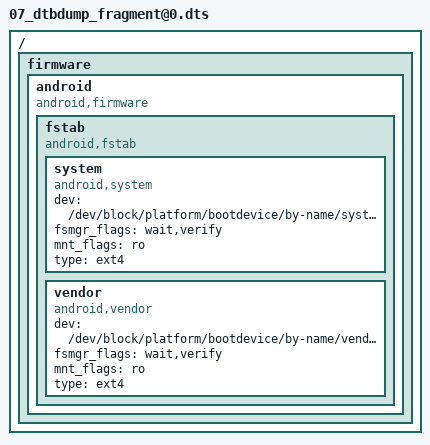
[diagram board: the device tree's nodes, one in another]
/dts-v1/;

/ {

	__fixups__ {
		accdet = "/fragment@17:target:0", "/fragment@65:target:0";
		apuart0 = "/fragment@22:target:0";
		audgpio = "/fragment@18:target:0";
		auxadc = "/fragment@45:target:0";
		charger = "/fragment@34:target:0";
		chosen = "/fragment@0:target:0";
		consys = "/fragment@21:target:0";
		fpc_interrupt = "/fragment@41:target:0";
		goodix_fp = "/fragment@67:target:0";
		goodix_optical_fp = "/fragment@39:target:0";
		gpio = "/fragment@60:target:0";
		gpio_usage_mapping = "/fragment@59:target:0";
		gyro = "/fragment@64:target:0";
		i2c0 = "/fragment@13:target:0", "/fragment@47:target:0";
		i2c1 = "/fragment@48:target:0";
		i2c10 = "/fragment@57:target:0";
		i2c11 = "/fragment@58:target:0";
		i2c2 = "/fragment@49:target:0";
		i2c3 = "/fragment@4:target:0", "/fragment@7:target:0", "/fragment@50:target:0";
		i2c4 = "/fragment@51:target:0";
		i2c5 = "/fragment@9:target:0", "/fragment@52:target:0";
		i2c6 = "/fragment@53:target:0", "/fragment@84:target:0";
		i2c7 = "/fragment@54:target:0";
		i2c8 = "/fragment@55:target:0";
		i2c9 = "/fragment@56:target:0";
		irtx_pwm = "/fragment@26:target:0";
		kd_camera_hw1 = "/fragment@25:target:0", "/fragment@81:target:0";
		keypad = "/fragment@30:target:0", "/fragment@83:target:0";
		main_pmic = "/fragment@70:target:0";
		md1_sim1_hot_plug_eint = "/fragment@72:target:0";
		md1_sim2_hot_plug_eint = "/fragment@73:target:0";
		mediatek_phy_tuning = "/fragment@2:target:0";
		motor_drv = "/fragment@12:target:0";
		motor_pl = "/fragment@11:target:0";
		mrdump_ext_rst = "/fragment@61:target:0";
		msdc1 = "/fragment@32:target:0";
		msdc1_ins = "/fragment@63:target:0";
		mt6370_pmu = "/fragment@28:target:0";
		mt6370_typec = "/fragment@29:target:0";
		mt_pmic_vcama1_ldo_reg = "/fragment@25/__overlay__:cam0_vcama-supply:0", "/fragment@74:target:0", "/fragment@81/__overlay__:vcama-supply:0";
		mt_pmic_vcama2_ldo_reg = "/fragment@25/__overlay__:cam1_vcama-supply:0", "/fragment@25/__overlay__:cam2_vcama-supply:0", "/fragment@75:target:0", "/fragment@81/__overlay__:vcama_sub-supply:0", "/fragment@81/__overlay__:vcama_main2-supply:0";
		mt_pmic_vcamd_ldo_reg = "/fragment@25/__overlay__:cam2_vcamd-supply:0", "/fragment@78:target:0", "/fragment@81/__overlay__:vcamd_main2-supply:0";
		mt_pmic_vcamio_ldo_reg = "/fragment@25/__overlay__:cam0_vcamio-supply:0", "/fragment@25/__overlay__:cam1_vcamio-supply:0", "/fragment@25/__overlay__:cam2_vcamio-supply:0", "/fragment@79:target:0", "/fragment@81/__overlay__:vcamio-supply:0", "/fragment@81/__overlay__:vcamio_sub-supply:0", "/fragment@81/__overlay__:vcamio_main2-supply:0";
		mt_pmic_vldo28_ldo_reg = "/fragment@80:target:0", "/fragment@81/__overlay__:vcamaf-supply:0", "/fragment@82/__overlay__:vtouch-supply:0";
		mt_pmic_vsim1_ldo_reg = "/fragment@76:target:0";
		mt_pmic_vsim2_ldo_reg = "/fragment@77:target:0";
		mtkfb = "/fragment@6:target:0";
		odm = "/fragment@1:target:0";
		oppo_fp_common = "/fragment@44:target:0";
		otg_iddig = "/fragment@15:target:0", "/fragment@68:target:0";
		pio = "/fragment@1/__overlay__/kpd_volume_up:interrupt-parent:0", "/fragment@1/__overlay__/kpd_volume_down:interrupt-parent:0", "/fragment@1/__overlay__/oppo_devinfo:Hw,sub_hwid_1:0", "/fragment@1/__overlay__/oppo_devinfo:Hw,sub_hwid_2:0", "/fragment@1/__overlay__/oppo_charger:qcom,chargerid_switch-gpio:0", "/fragment@5:target:0", "/fragment@8:target:0", "/fragment@9/__overlay__/bq25601d-charger@6b:interrupt-parent:0", "/fragment@9/__overlay__/bq25601d-charger@6b:chg-irq-gpio:0", "/fragment@9/__overlay__/bq25890h-charger@6a:interrupt-parent:0", "/fragment@9/__overlay__/bq25890h-charger@6a:chg-irq-gpio:0", "/fragment@10:target:0", "/fragment@12/__overlay__:boost-gpio:0", "/fragment@12/__overlay__:sleep-gpio:0", "/fragment@12/__overlay__:dir-gpio:0", "/fragment@12/__overlay__:step-gpio:0", "/fragment@13/__overlay__/dhall0-m1120@0f:interrupt-parent:0", "/fragment@13/__overlay__/dhall0-m1120@0f:dhall,irq-gpio:0", "/fragment@13/__overlay__/dhall0-m1120@0f:hall-power-gpio:0", "/fragment@13/__overlay__/dhall1-m1120@0c:interrupt-parent:0", "/fragment@13/__overlay__/dhall1-m1120@0c:dhall,irq-gpio:0", "/fragment@13/__overlay__/dhall1-m1120@0c:hall-power-gpio:0", "/fragment@14:target:0", "/fragment@16:target:0", "/fragment@19:target:0", "/fragment@20:target:0", "/fragment@23:target:0", "/fragment@24:target:0", "/fragment@27:target:0", "/fragment@28/__overlay__:mt6370,intr_gpio:0", "/fragment@29/__overlay__:mt6370pd,intr_gpio:0", "/fragment@30/__overlay__:keypad,volume-up:0", "/fragment@30/__overlay__:keypad,volume-down:0", "/fragment@31:target:0", "/fragment@33:target:0", "/fragment@35:target:0", "/fragment@36:target:0", "/fragment@37/__overlay__/touchscreen@0:reset-gpio:0", "/fragment@37/__overlay__/touchscreen@0:interrupt-parent:0", "/fragment@37/__overlay__/touchscreen@0:irq-gpio:0", "/fragment@37/__overlay__/touchscreen@0:lcd-reset-gpio:0", "/fragment@38:target:0", "/fragment@39/__overlay__:interrupt-parent:0", "/fragment@39/__overlay__:goodix,gpio_irq:0", "/fragment@39/__overlay__:goodix,gpio_reset:0", "/fragment@39/__overlay__:goodix,gpio_ldo:0", "/fragment@39/__overlay__:goodix,gpio_cs:0", "/fragment@40:target:0", "/fragment@41/__overlay__:fpc,irq-gpio:0", "/fragment@41/__overlay__:fpc,reset-gpio:0", "/fragment@41/__overlay__:fpc,vdd-en:0", "/fragment@41/__overlay__:fpc,gpio_cs:0", "/fragment@42/__overlay__/fingerprint@0:ldo_gpio:0", "/fragment@43:target:0", "/fragment@44/__overlay__:oppo,fp-id0:0", "/fragment@48/__overlay__/alsps@51:interrupt-parent:0", "/fragment@59/__overlay__:GPIO_SIM2_SIO:0", "/fragment@59/__overlay__:GPIO_SIM2_SRST:0", "/fragment@59/__overlay__:GPIO_SIM2_SCLK:0", "/fragment@59/__overlay__:GPIO_SIM1_SCLK:0", "/fragment@59/__overlay__:GPIO_SIM1_SRST:0", "/fragment@59/__overlay__:GPIO_SIM1_SIO:0", "/fragment@59/__overlay__:GPIO_SIM1_HOT_PLUG:0", "/fragment@61/__overlay__:interrupt-parent:0", "/fragment@61/__overlay__:deb-gpios:0", "/fragment@62/__overlay__:interrupt-parent:0", "/fragment@63/__overlay__:interrupt-parent:0", "/fragment@63/__overlay__:deb-gpios:0", "/fragment@64/__overlay__:interrupt-parent:0", "/fragment@65/__overlay__:interrupt-parent:0", "/fragment@65/__overlay__:deb-gpios:0", "/fragment@66/__overlay__:interrupt-parent:0", "/fragment@67/__overlay__:interrupt-parent:0", "/fragment@68/__overlay__:interrupt-parent:0", "/fragment@69/__overlay__:interrupt-parent:0", "/fragment@69/__overlay__:deb-gpios:0", "/fragment@70/__overlay__:interrupt-parent:0", "/fragment@71/__overlay__:interrupt-parent:0", "/fragment@85:target:0", "/fragment@86:target:0";
		pmic_clock_buffer_ctrl = "/fragment@46:target:0";
		rt9465_slave_chr = "/fragment@66:target:0";
		scp = "/fragment@3:target:0";
		smart_pa = "/fragment@71:target:0";
		spi0 = "/fragment@42:target:0";
		spi3 = "/fragment@37:target:0";
		swtp = "/fragment@69:target:0", "/fragment@87:target:0";
		touch = "/fragment@62:target:0", "/fragment@82:target:0";
	};

	__local_fixups__ {

		fragment@1 {

			__overlay__ {

				oppo_charger {
					pinctrl-0 = <0x0>;
					pinctrl-1 = <0x0>;
					pinctrl-2 = <0x0>;
				};

				oppo_devinfo {
					pinctrl-0 = <0x0>;
					pinctrl-1 = <0x0 0x4>;
					pinctrl-2 = <0x0 0x4>;
				};
			};
		};

		fragment@12 {

			__overlay__ {
				pinctrl-0 = <0x0>;
				pinctrl-1 = <0x0 0x4 0x8 0xc>;
				pinctrl-2 = <0x0 0x4 0x8 0xc>;
			};
		};

		fragment@13 {

			__overlay__ {

				dhall0-m1120@0f {
					pinctrl-0 = <0x0>;
					pinctrl-1 = <0x0>;
					pinctrl-2 = <0x0>;
				};

				dhall1-m1120@0c {
					pinctrl-0 = <0x0>;
					pinctrl-1 = <0x0>;
					pinctrl-2 = <0x0>;
				};
			};
		};

		fragment@15 {

			__overlay__ {
				pinctrl-0 = <0x0>;
				pinctrl-1 = <0x0>;
				pinctrl-2 = <0x0>;
			};
		};

		fragment@18 {

			__overlay__ {
				pinctrl-0 = <0x0>;
				pinctrl-1 = <0x0>;
				pinctrl-10 = <0x0>;
				pinctrl-11 = <0x0>;
				pinctrl-2 = <0x0>;
				pinctrl-3 = <0x0>;
				pinctrl-4 = <0x0>;
				pinctrl-5 = <0x0>;
				pinctrl-6 = <0x0>;
				pinctrl-7 = <0x0>;
				pinctrl-8 = <0x0>;
				pinctrl-9 = <0x0>;
			};
		};

		fragment@21 {

			__overlay__ {
				pinctrl-0 = <0x0>;
				pinctrl-1 = <0x0>;
				pinctrl-2 = <0x0>;
				pinctrl-3 = <0x0>;
			};
		};

		fragment@22 {

			__overlay__ {
				pinctrl-0 = <0x0>;
				pinctrl-1 = <0x0>;
				pinctrl-2 = <0x0>;
				pinctrl-3 = <0x0>;
				pinctrl-4 = <0x0>;
				pinctrl-5 = <0x0>;
				pinctrl-6 = <0x0>;
			};
		};

		fragment@25 {

			__overlay__ {
				pinctrl-0 = <0x0>;
				pinctrl-1 = <0x0>;
				pinctrl-10 = <0x0>;
				pinctrl-11 = <0x0>;
				pinctrl-12 = <0x0>;
				pinctrl-13 = <0x0>;
				pinctrl-14 = <0x0>;
				pinctrl-15 = <0x0>;
				pinctrl-16 = <0x0>;
				pinctrl-17 = <0x0>;
				pinctrl-18 = <0x0>;
				pinctrl-19 = <0x0>;
				pinctrl-2 = <0x0>;
				pinctrl-20 = <0x0>;
				pinctrl-21 = <0x0>;
				pinctrl-22 = <0x0>;
				pinctrl-23 = <0x0>;
				pinctrl-24 = <0x0>;
				pinctrl-25 = <0x0>;
				pinctrl-3 = <0x0>;
				pinctrl-4 = <0x0>;
				pinctrl-5 = <0x0>;
				pinctrl-6 = <0x0>;
				pinctrl-7 = <0x0>;
				pinctrl-8 = <0x0>;
				pinctrl-9 = <0x0>;
			};
		};

		fragment@26 {

			__overlay__ {
				pinctrl-0 = <0x0>;
				pinctrl-1 = <0x0>;
			};
		};

		fragment@30 {

			__overlay__ {
				pinctrl-0 = <0x0>;
				pinctrl-1 = <0x0>;
			};
		};

		fragment@32 {

			__overlay__ {
				pinctrl-0 = <0x0>;
				pinctrl-1 = <0x0>;
			};
		};

		fragment@39 {

			__overlay__ {
				pinctrl-0 = <0x0>;
				pinctrl-1 = <0x0>;
				pinctrl-2 = <0x0>;
				pinctrl-3 = <0x0>;
				pinctrl-4 = <0x0>;
			};
		};

		fragment@41 {

			__overlay__ {
				pinctrl-0 = <0x0 0x4 0x8>;
				pinctrl-1 = <0x0>;
			};
		};

		fragment@44 {

			__overlay__ {
				pinctrl-0 = <0x0>;
			};
		};

		fragment@6 {

			__overlay__ {
				pinctrl-0 = <0x0>;
				pinctrl-1 = <0x0>;
				pinctrl-10 = <0x0>;
				pinctrl-11 = <0x0>;
				pinctrl-12 = <0x0>;
				pinctrl-13 = <0x0 0x4>;
				pinctrl-14 = <0x0 0x4>;
				pinctrl-2 = <0x0>;
				pinctrl-3 = <0x0>;
				pinctrl-4 = <0x0>;
				pinctrl-5 = <0x0>;
				pinctrl-6 = <0x0>;
				pinctrl-7 = <0x0>;
				pinctrl-8 = <0x0>;
				pinctrl-9 = <0x0>;
			};
		};

		fragment@7 {

			__overlay__ {

				tfa98xx@35 {
					pinctrl-0 = <0x0>;
					pinctrl-1 = <0x0>;
					pinctrl-2 = <0x0>;
				};
			};
		};

		fragment@84 {

			__overlay__ {
				pinctrl-0 = <0x0>;
				pinctrl-1 = <0x0>;
			};
		};
	};

	__symbols__ {
		alsps_mtk = "/fragment@48/__overlay__/alsps@51";
		aud_clk_mosi_off = "/fragment@19/__overlay__/aud_clk_mosi_off";
		aud_clk_mosi_on = "/fragment@19/__overlay__/aud_clk_mosi_on";
		aud_dat_miso_off = "/fragment@19/__overlay__/aud_dat_miso_off";
		aud_dat_miso_on = "/fragment@19/__overlay__/aud_dat_miso_on";
		aud_dat_mosi_off = "/fragment@19/__overlay__/aud_dat_mosi_off";
		aud_dat_mosi_on = "/fragment@19/__overlay__/aud_dat_mosi_on";
		aud_pins_hpamp_high = "/fragment@19/__overlay__/audhpamphigh";
		aud_pins_hpamp_low = "/fragment@19/__overlay__/audhpamplow";
		aud_pins_i2s0_mode0 = "/fragment@19/__overlay__/audi2s0mode0";
		aud_pins_i2s0_mode1 = "/fragment@19/__overlay__/audi2s0mode1";
		aud_pins_i2s1_mode0 = "/fragment@19/__overlay__/audi2s1mode0";
		aud_pins_i2s1_mode1 = "/fragment@19/__overlay__/audi2s1mode1";
		barometer_mtk = "/fragment@48/__overlay__/barometer@77";
		bat_gm30 = "/fragment@1/__overlay__/bat_gm30";
		boost_active = "/fragment@10/__overlay__/boost_active";
		boost_sleep = "/fragment@10/__overlay__/boost_sleep";
		camera_main_af_mtk = "/fragment@51/__overlay__/camera_main_af@72";
		camera_main_eeprom_mtk = "/fragment@51/__overlay__/camera_main_eeprom@50";
		camera_main_mtk = "/fragment@51/__overlay__/camera_main@1a";
		camera_main_two_af_mtk = "/fragment@51/__overlay__/camera_main_two_af@72";
		camera_main_two_eeprom_mtk = "/fragment@49/__overlay__/camera_main_two_eeprom@51";
		camera_main_two_mtk = "/fragment@49/__overlay__/camera_main_two@10";
		camera_pins_cam0_mclk_2ma = "/fragment@24/__overlay__/camera_pins_cam0_mclk_2ma";
		camera_pins_cam0_mclk_4ma = "/fragment@24/__overlay__/camera_pins_cam0_mclk_4ma";
		camera_pins_cam0_mclk_6ma = "/fragment@24/__overlay__/camera_pins_cam0_mclk_6ma";
		camera_pins_cam0_mclk_8ma = "/fragment@24/__overlay__/camera_pins_cam0_mclk_8ma";
		camera_pins_cam0_mclk_off = "/fragment@24/__overlay__/camera_pins_cam0_mclk_off";
		camera_pins_cam0_rst_0 = "/fragment@24/__overlay__/cam0@0";
		camera_pins_cam0_rst_1 = "/fragment@24/__overlay__/cam0@1";
		camera_pins_cam0_vcamd_0 = "/fragment@24/__overlay__/cam0@vcam0";
		camera_pins_cam0_vcamd_1 = "/fragment@24/__overlay__/cam0@vcam1";
		camera_pins_cam1_mclk_2ma = "/fragment@24/__overlay__/camera_pins_cam1_mclk_2ma";
		camera_pins_cam1_mclk_4ma = "/fragment@24/__overlay__/camera_pins_cam1_mclk_4ma";
		camera_pins_cam1_mclk_6ma = "/fragment@24/__overlay__/camera_pins_cam1_mclk_6ma";
		camera_pins_cam1_mclk_8ma = "/fragment@24/__overlay__/camera_pins_cam1_mclk_8ma";
		camera_pins_cam1_mclk_off = "/fragment@24/__overlay__/camera_pins_cam1_mclk_off";
		camera_pins_cam1_rst_0 = "/fragment@24/__overlay__/cam1@0";
		camera_pins_cam1_rst_1 = "/fragment@24/__overlay__/cam1@1";
		camera_pins_cam1_vcamd_0 = "/fragment@24/__overlay__/cam1@vcamd0";
		camera_pins_cam1_vcamd_1 = "/fragment@24/__overlay__/cam1@vcamd1";
		camera_pins_cam2_mclk_2ma = "/fragment@24/__overlay__/camera_pins_cam2_mclk_2ma";
		camera_pins_cam2_mclk_4ma = "/fragment@24/__overlay__/camera_pins_cam2_mclk_4ma";
		camera_pins_cam2_mclk_6ma = "/fragment@24/__overlay__/camera_pins_cam2_mclk_6ma";
		camera_pins_cam2_mclk_8ma = "/fragment@24/__overlay__/camera_pins_cam2_mclk_8ma";
		camera_pins_cam2_mclk_off = "/fragment@24/__overlay__/camera_pins_cam2_mclk_off";
		camera_pins_cam2_rst_0 = "/fragment@24/__overlay__/cam2@0";
		camera_pins_cam2_rst_1 = "/fragment@24/__overlay__/cam2@1";
		camera_pins_default = "/fragment@24/__overlay__/camdefault";
		camera_sub_eeprom_mtk = "/fragment@51/__overlay__/camera_sub_eeprom@54";
		camera_sub_mtk = "/fragment@51/__overlay__/camera_sub@35";
		cap_touch_mtk = "/fragment@47/__overlay__/cap_touch@5d";
		ccu_sensor_i2c_2_hw_mtk = "/fragment@49/__overlay__/ccu_sensor_i2c_2_hw@36";
		ccu_sensor_i2c_4_hw_mtk = "/fragment@51/__overlay__/ccu_sensor_i2c_4_hw@33";
		charger_pins_default = "/fragment@35/__overlay__/eint0default";
		charger_pins_eint_output0 = "/fragment@35/__overlay__/charger_gpio_as_output_low";
		charger_pins_eint_output1 = "/fragment@35/__overlay__/charger_gpio_as_output_high";
		consys_pins_default = "/fragment@20/__overlay__/consys_default";
		dir_active = "/fragment@10/__overlay__/dir_active";
		dir_sleep = "/fragment@10/__overlay__/dir_sleep";
		fpc_irq_default = "/fragment@40/__overlay__/fpc_irq_default";
		fpc_pwr_default = "/fragment@40/__overlay__/fpc_pwr_default";
		fpc_reset_default = "/fragment@40/__overlay__/fpc_reset_default";
		fuelgauge = "/fragment@1/__overlay__/fuelgauge";
		goodix_irq_no_pull = "/fragment@38/__overlay__/goodix_irq_no_pull";
		goodix_irq_out_low = "/fragment@38/__overlay__/goodix_irq_out_low";
		goodix_ldo_default = "/fragment@38/__overlay__/goodix_ldo_default";
		goodix_reset_default = "/fragment@38/__overlay__/goodix_reset_default";
		gpio41_gpio_mode = "/fragment@16/__overlay__/id_output_low";
		gpio41_mode1_iddig = "/fragment@16/__overlay__/id_init";
		gpio_fpc_cs_func = "/fragment@40/__overlay__/gpio_fpc_cs_func";
		gpio_goodix_cs_func = "/fragment@38/__overlay__/gpio_goodix_cs_func";
		gpio_id0_default = "/fragment@43/__overlay__/gpio_id0_default";
		gpslna_pins_init = "/fragment@20/__overlay__/gpslna@0";
		gpslna_pins_oh = "/fragment@20/__overlay__/gpslna@1";
		gpslna_pins_ol = "/fragment@20/__overlay__/gpslna@2";
		hall0_interrupt_input = "/fragment@14/__overlay__/hall0_interrupt_input";
		hall1_interrupt_input = "/fragment@14/__overlay__/hall1_interrupt_input";
		hall_power_down = "/fragment@14/__overlay__/hall_power_down";
		hall_power_up = "/fragment@14/__overlay__/hall_power_up";
		hw_pins_default = "/fragment@86/__overlay__/default@hw_sub_id";
		hw_pins_sub_id1_active = "/fragment@86/__overlay__/active@id1";
		hw_pins_sub_id1_sleep = "/fragment@86/__overlay__/sleep@id1";
		hw_pins_sub_id2_active = "/fragment@86/__overlay__/active@id2";
		hw_pins_sub_id2_sleep = "/fragment@86/__overlay__/sleep@id2";
		i2c6_i2c_state = "/fragment@85/__overlay__/i2c6_sda_i2c_state";
		i2c6_output_low_state = "/fragment@85/__overlay__/i2c6_sda_output_low_state";
		iddig_default = "/fragment@16/__overlay__/id_default";
		irtx_gpio_led_default = "/fragment@27/__overlay__/irtx_gpio_led_def@gpio90";
		irtx_gpio_led_set = "/fragment@27/__overlay__/irtx_gpio_led_set@gpio90";
		kpd_volume_down = "/fragment@1/__overlay__/kpd_volume_down";
		kpd_volume_up = "/fragment@1/__overlay__/kpd_volume_up";
		led0 = "/fragment@1/__overlay__/led@0";
		led1 = "/fragment@1/__overlay__/led@1";
		led2 = "/fragment@1/__overlay__/led@2";
		led3 = "/fragment@1/__overlay__/led@3";
		led4 = "/fragment@1/__overlay__/led@4";
		led5 = "/fragment@1/__overlay__/led@5";
		led6 = "/fragment@1/__overlay__/led@6";
		motor_default = "/fragment@10/__overlay__/motor_default";
		msdc1_off = "/fragment@33/__overlay__/sd0@1";
		msdc1_on = "/fragment@33/__overlay__/sd0@0";
		msensor_mtk = "/fragment@48/__overlay__/msensor@0c";
		mtkfb_pins_default = "/fragment@5/__overlay__/default";
		mtkfb_pins_lcd_1p8_en0 = "/fragment@5/__overlay__/lcd_1p8_en0_gpio";
		mtkfb_pins_lcd_1p8_en1 = "/fragment@5/__overlay__/lcd_1p8_en1_gpio";
		mtkfb_pins_lcd_bias_enn0 = "/fragment@5/__overlay__/lcd_bias_enn0_gpio";
		mtkfb_pins_lcd_bias_enn1 = "/fragment@5/__overlay__/lcd_bias_enn1_gpio";
		mtkfb_pins_lcd_bias_enp0 = "/fragment@5/__overlay__/lcd_bias_enp0_gpio";
		mtkfb_pins_lcd_bias_enp1 = "/fragment@5/__overlay__/lcd_bias_enp1_gpio";
		mtkfb_pins_lcd_bl_en0 = "/fragment@5/__overlay__/lcd_bl_en0_gpio";
		mtkfb_pins_lcd_bl_en1 = "/fragment@5/__overlay__/lcd_bl_en1_gpio";
		mtkfb_pins_lcm_reset0 = "/fragment@5/__overlay__/lcm_rst_out0_gpio";
		mtkfb_pins_lcm_reset1 = "/fragment@5/__overlay__/lcm_rst_out1_gpio";
		mtkfb_pins_mode_te_gpio = "/fragment@5/__overlay__/mode_te_gpio";
		mtkfb_pins_mode_te_te = "/fragment@5/__overlay__/mode_te_te";
		mtkfb_pins_spi_clk_en0 = "/fragment@5/__overlay__/spi_clk_en0_gpio";
		mtkfb_pins_spi_clk_en1 = "/fragment@5/__overlay__/spi_clk_en1_gpio";
		mtkfb_pins_spi_cs_en0 = "/fragment@5/__overlay__/spi_csn_en0_gpio";
		mtkfb_pins_spi_cs_en1 = "/fragment@5/__overlay__/spi_csn_en1_gpio";
		nfc_mtk = "/fragment@50/__overlay__/nfc@08";
		oppo_charger = "/fragment@1/__overlay__/oppo_charger";
		oppo_devinfo = "/fragment@1/__overlay__/oppo_devinfo";
		oppo_fp = "/fragment@42/__overlay__/fingerprint@0";
		oppo_project = "/fragment@1/__overlay__/oppo_project";
		oppo_sensor = "/fragment@1/__overlay__/oppo_sensor";
		pwm_active = "/fragment@10/__overlay__/pwm_active";
		pwm_sleep = "/fragment@10/__overlay__/pwm_sleep";
		slave_charger_mtk = "/fragment@53/__overlay__/slave_charger@4b";
		sleep_active = "/fragment@10/__overlay__/sleep_active";
		sleep_sleep = "/fragment@10/__overlay__/sleep_sleep";
		speaker_amp_mtk = "/fragment@53/__overlay__/speaker_amp@34";
		strobe_main_2_mtk = "/fragment@51/__overlay__/strobe_main_2@64";
		strobe_main_mtk = "/fragment@51/__overlay__/strobe_main@63";
		subpmic_pmu_mtk = "/fragment@52/__overlay__/subpmic_pmu@37";
		tfa98xxresetdefault = "/fragment@8/__overlay__/tfa98xxrstdefault";
		tfa98xxresethigh = "/fragment@8/__overlay__/tfa98xxrsthigh";
		tfa98xxresetlow = "/fragment@8/__overlay__/tfa98xxrstlow";
		uart0_gpio_def_cfg = "/fragment@23/__overlay__/uart0gpiodefault";
		uart0_rx_clr_cfg = "/fragment@23/__overlay__/uart0_rx_clear@gpio95";
		uart0_rx_gpio_input = "/fragment@23/__overlay__/uart0_rx_gpio@gpio95";
		uart0_rx_set_cfg = "/fragment@23/__overlay__/uart0_rx_set@gpio95";
		uart0_tx_clr_cfg = "/fragment@23/__overlay__/uart0_tx_clear@gpio96";
		uart0_tx_gpio_input = "/fragment@23/__overlay__/uart0_tx_gpio@gpio96";
		uart0_tx_set_cfg = "/fragment@23/__overlay__/uart0_tx_set@gpio96";
		usb_c_pinctrl = "/fragment@1/__overlay__/usb_c_pinctrl";
		usb_type_c_mtk = "/fragment@52/__overlay__/usb_type_c@4e";
		vibrator0 = "/fragment@1/__overlay__/vibrator@0";
		volume_down_gpio_eint = "/fragment@31/__overlay__/volume_down@0";
		volume_up_gpio_eint = "/fragment@31/__overlay__/volume_up@0";
	};

	firmware {

		android {
			compatible = "android,firmware";

			fstab {
				compatible = "android,fstab";

				system {
					compatible = "android,system";
					dev = "/dev/block/platform/bootdevice/by-name/system";
					fsmgr_flags = "wait,verify";
					mnt_flags = "ro";
					type = "ext4";
				};

				vendor {
					compatible = "android,vendor";
					dev = "/dev/block/platform/bootdevice/by-name/vendor";
					fsmgr_flags = "wait,verify";
					mnt_flags = "ro";
					type = "ext4";
				};
			};
		};
	};

	fragment@0 {
		target = <0xffffffff>;

		__overlay__ {
			atag,videolfb-fb_base_h = <0x0>;
			atag,videolfb-fb_base_l = "^`P";
			atag,videolfb-fps = <0x1770>;
			atag,videolfb-islcm_inited = <0x0>;
			atag,videolfb-islcmfound = <0x1>;
			atag,videolfb-lcmname = "nt35595_fhd_dsi_cmd_truly_nt50358_drv";
			atag,videolfb-vramSize = <0x17bb000>;
		};
	};

	fragment@1 {
		target = <0xffffffff>;

		__overlay__ {

			bat_gm30 {
				CAR_TUNE_VALUE = <0x64>;
				DIFFERENCE_FULLOCV_ITH = <0x15e>;
				EMBEDDED_SEL = <0x1>;
				FG_METER_RESISTANCE = <0x32>;
				KEEP_100_PERCENT = <0x3>;
				PMIC_MIN_VOL = <0x85fc>;
				PMIC_SHUTDOWN_CURRENT = <0x14>;
				POWERON_SYSTEM_IBOOT = <0x1f4>;
				Q_MAX_SYS_VOLTAGE_BAT0 = <0xd16>;
				Q_MAX_SYS_VOLTAGE_BAT1 = <0xd16>;
				Q_MAX_SYS_VOLTAGE_BAT2 = <0xd16>;
				Q_MAX_SYS_VOLTAGE_BAT3 = <0xd16>;
				R_FG_VALUE = <0xa>;
				SHUTDOWN_1_TIME = <0x3c>;
				SHUTDOWN_GAUGE0_VOLTAGE = <0x84d0>;
				TEMPERATURE_T0 = <0x32>;
				TEMPERATURE_T1 = <0x19>;
				TEMPERATURE_T2 = <0xa>;
				TEMPERATURE_T3 = <0x0>;
				TEMPERATURE_T4 = <0xfffffff6>;
				battery0_profile_t0 = <0x0 0xaad2 0x401 0x194 0xaa51 0x401 0x328 0xa9dc 0x410 0x4bc 0xa965 0x40f 0x651 0xa8ef 0x407 0x7e5 0xa885 0x41a 0x979 0xa80c 0x41a 0xb0d 0xa792 0x409 0xca1 0xa719 0x401 0xe35 0xa6a3 0x408 0xfc9 0xa632 0x41d 0x115e 0xa5c0 0x431 0x12f2 0xa548 0x421 0x1486 0xa4d4 0x427 0x161a 0xa463 0x43b 0x17ae 0xa3f0 0x445 0x1942 0xa377 0x41c 0x1ad6 0xa303 0x41a 0x1c6b 0xa28c 0x41a 0x1dff 0xa21a 0x424 0x1f93 0xa1af 0x433 0x2127 0xa13e 0x433 0x22bb 0xa0d5 0x448 0x244f 0xa066 0x43c 0x25e3 0x9ffd 0x43e 0x2778 0x9f9a 0x44c 0x290c 0x9f31 0x44c 0x2aa0 0x9ec8 0x44c 0x2c34 0x9e65 0x44c 0x2dc8 0x9e04 0x44c 0x2f5c 0x9da6 0x45b 0x30f0 0x9d49 0x47e 0x3285 0x9ce0 0x47e 0x3419 0x9c7e 0x46c 0x35ad 0x9c2d 0x473 0x3741 0x9bde 0x487 0x38d5 0x9b85 0x497 0x3a69 0x9b2c 0x497 0x3bfd 0x9ae2 0x4be 0x3d92 0x9a8d 0x4d8 0x3f26 0x9a2f 0x4ec 0x40ba 0x99c0 0x4e0 0x424e 0x992f 0x47b 0x43e2 0x989d 0x42a 0x4576 0x9833 0x41a 0x470a 0x97df 0x425 0x489f 0x9797 0x42c 0x4a33 0x974f 0x41c 0x4bc7 0x9717 0x430 0x4d5b 0x96de 0x433 0x4eef 0x96a0 0x427 0x5083 0x9663 0x41a 0x5217 0x962b 0x41a 0x53ab 0x95fb 0x41a 0x5540 0x95d2 0x42c 0x56d4 0x959f 0x426 0x5868 0x956d 0x42b 0x59fc 0x9544 0x448 0x5b90 0x951b 0x433 0x5d24 0x94f3 0x433 0x5eb8 0x94ca 0x442 0x604d 0x94a6 0x44c 0x61e1 0x9483 0x447 0x6375 0x945b 0x434 0x6509 0x943b 0x448 0x669d 0x9420 0x45c 0x6831 0x9403 0x465 0x69c5 0x93e0 0x465 0x6b5a 0x93b6 0x463 0x6cee 0x937e 0x44f 0x6e82 0x9330 0x429 0x7016 0x92e9 0x427 0x71aa 0x92af 0x433 0x733e 0x927f 0x437 0x74d2 0x9256 0x44b 0x7667 0x9226 0x439 0x77fb 0x91f6 0x433 0x798f 0x91c9 0x433 0x7b23 0x91a3 0x433 0x7cb7 0x9182 0x433 0x7e4b 0x9162 0x45b 0x7fdf 0x9129 0x456 0x8174 0x90e8 0x442 0x8308 0x90a8 0x433 0x849c 0x9067 0x433 0x8630 0x901e 0x433 0x87c4 0x8fd5 0x412 0x8958 0x8fb1 0x40d 0x8aec 0x8fa9 0x427 0x8c81 0x8fa0 0x44c 0x8e15 0x8f90 0x44c 0x8fa9 0x8f79 0x481 0x913d 0x8f41 0x4a4 0x92d1 0x8e98 0x48f 0x9465 0x8d48 0x456 0x95f9 0x8b6b 0x493 0x978e 0x88e1 0x4d0 0x9922 0x853c 0x545 0x9ab6 0x7e14 0xd68 0x9c4a 0x7026 0x1211>;
				battery0_profile_t0_num = <0x64>;
				battery0_profile_t1 = <0x0 0xaa96 0x4c9 0x194 0xaa15 0x4c9 0x328 0xa9a6 0x4e8 0x4bc 0xa934 0x4f0 0x651 0xa8ba 0x4e2 0x7e5 0xa83f 0x4e2 0x979 0xa7c6 0x4e2 0xb0d 0xa75a 0x4f3 0xca1 0xa6e7 0x4ef 0xe35 0xa671 0x4e9 0xfc9 0xa600 0x4fb 0x115e 0xa58e 0x4fb 0x12f2 0xa516 0x4fb 0x1486 0xa4a2 0x4fb 0x161a 0xa42e 0x4f3 0x17ae 0xa3b6 0x4e6 0x1942 0xa345 0x4fa 0x1ad6 0xa2d3 0x4fb 0x1c6b 0xa261 0x4fb 0x1dff 0xa1f2 0x505 0x1f93 0xa187 0x514 0x2127 0xa116 0x514 0x22bb 0xa0ad 0x514 0x244f 0xa03e 0x514 0x25e3 0x9fd5 0x514 0x2778 0x9f74 0x521 0x290c 0x9f12 0x546 0x2aa0 0x9eb9 0x546 0x2c34 0x9e52 0x557 0x2dc8 0x9dee 0x56c 0x2f5c 0x9d87 0x578 0x30f0 0x9d17 0x578 0x3285 0x9cae 0x578 0x3419 0x9c4a 0x58b 0x35ad 0x9bee 0x59f 0x3741 0x9b99 0x5b3 0x38d5 0x9b4a 0x5cc 0x3a69 0x9b01 0x5f4 0x3bfd 0x9ab8 0x609 0x3d92 0x9a58 0x60e 0x3f26 0x99e2 0x5e5 0x40ba 0x995c 0x58e 0x424e 0x98c9 0x529 0x43e2 0x9858 0x4ed 0x4576 0x97fb 0x4e2 0x470a 0x97ab 0x4d6 0x489f 0x9766 0x4c9 0x4a33 0x9726 0x4c9 0x4bc7 0x96ed 0x4c9 0x4d5b 0x96b5 0x4c9 0x4eef 0x967c 0x4c9 0x5083 0x9643 0x4c9 0x5217 0x960c 0x4cd 0x53ab 0x95e4 0x4e1 0x5540 0x95b4 0x4e2 0x56d4 0x9589 0x4e2 0x5868 0x9561 0x4ec 0x59fc 0x9538 0x4fb 0x5b90 0x9510 0x4fb 0x5d24 0x94e7 0x4fb 0x5eb8 0x94c5 0x4fb 0x604d 0x94a4 0x506 0x61e1 0x9484 0x514 0x6375 0x9464 0x516 0x6509 0x944c 0x52a 0x669d 0x9426 0x51c 0x6831 0x9407 0x520 0x69c5 0x93e9 0x526 0x6b5a 0x93c2 0x517 0x6cee 0x93a1 0x52b 0x6e82 0x9379 0x51b 0x7016 0x9346 0x4f9 0x71aa 0x9314 0x4d9 0x733e 0x92ec 0x4cd 0x74d2 0x92c3 0x4e1 0x7667 0x929b 0x4e2 0x77fb 0x926d 0x4d3 0x798f 0x9248 0x4d3 0x7b23 0x922c 0x4e2 0x7cb7 0x9203 0x4e2 0x7e4b 0x91ca 0x4cd 0x7fdf 0x918a 0x4d9 0x8174 0x9152 0x4ed 0x8308 0x911a 0x4f4 0x849c 0x90d0 0x4e2 0x8630 0x9080 0x4e2 0x87c4 0x904a 0x4d1 0x8958 0x9033 0x4e2 0x8aec 0x9028 0x4fb 0x8c81 0x9018 0x4fb 0x8e15 0x9007 0x4fb 0x8fa9 0x8ff7 0x546 0x913d 0x8fa3 0x55f 0x92d1 0x8ec3 0x55f 0x9465 0x8d36 0x563 0x95f9 0x8b19 0x578 0x978e 0x8815 0x5ef 0x9922 0x8366 0x70e 0x9ab6 0x7a4a 0x1a58 0x9c4a 0x74a4 0x1ccf>;
				battery0_profile_t1_num = <0x64>;
				battery0_profile_t2 = <0x0 0xa9f6 0x78a 0x194 0xa96d 0x786 0x328 0xa8f0 0x7b3 0x4bc 0xa872 0x7db 0x651 0xa7f3 0x7e9 0x7e5 0xa77a 0x7e9 0x979 0xa6fe 0x7e9 0xb0d 0xa68b 0x7e9 0xca1 0xa615 0x7f5 0xe35 0xa59c 0x7fb 0xfc9 0xa525 0x7ee 0x115e 0xa4bc 0x817 0x12f2 0xa444 0x809 0x1486 0xa3cf 0x802 0x161a 0xa35c 0x802 0x17ae 0xa2eb 0x802 0x1942 0xa27a 0x802 0x1ad6 0xa209 0x802 0x1c6b 0xa19d 0x81f 0x1dff 0xa134 0x834 0x1f93 0xa0c9 0x834 0x2127 0xa058 0x834 0x22bb 0x9ff7 0x849 0x244f 0x9f95 0x84d 0x25e3 0x9f38 0x864 0x2778 0x9edf 0x893 0x290c 0x9e83 0x8cc 0x2aa0 0x9e12 0x8e0 0x2c34 0x9d8c 0x8c0 0x2dc8 0x9d03 0x8a4 0x2f5c 0x9c86 0x8a0 0x30f0 0x9c21 0x8b7 0x3285 0x9bd9 0x8df 0x3419 0x9b90 0x8e3 0x35ad 0x9b41 0x8f1 0x3741 0x9aef 0x8fc 0x38d5 0x9a9e 0x900 0x3a69 0x9a4d 0x915 0x3bfd 0x99dd 0x8d9 0x3d92 0x9959 0x87f 0x3f26 0x98d4 0x824 0x40ba 0x985c 0x7e4 0x424e 0x97fb 0x7cf 0x43e2 0x97aa 0x7bb 0x4576 0x975f 0x7b7 0x470a 0x971a 0x7ab 0x489f 0x96df 0x7ac 0x4a33 0x96ad 0x7ce 0x4bc7 0x966c 0x7ba 0x4d5b 0x963a 0x7c9 0x4eef 0x9609 0x7d0 0x5083 0x95d9 0x7d0 0x5217 0x95a9 0x7d3 0x53ab 0x9581 0x7e7 0x5540 0x9550 0x7e9 0x56d4 0x9525 0x7f7 0x5868 0x94fd 0x802 0x59fc 0x94d6 0x807 0x5b90 0x94b6 0x81b 0x5d24 0x9496 0x82f 0x5eb8 0x946f 0x825 0x604d 0x944f 0x826 0x61e1 0x9437 0x83a 0x6375 0x941e 0x84d 0x6509 0x9406 0x84d 0x669d 0x93e7 0x84d 0x6831 0x93cb 0x84d 0x69c5 0x93b6 0x854 0x6b5a 0x93a4 0x866 0x6cee 0x9383 0x866 0x6e82 0x936a 0x878 0x7016 0x9347 0x871 0x71aa 0x931e 0x866 0x733e 0x92f4 0x866 0x74d2 0x92c4 0x866 0x7667 0x92a3 0x87a 0x77fb 0x927d 0x88e 0x798f 0x9250 0x8a2 0x7b23 0x921e 0x8bb 0x7cb7 0x91e5 0x8e3 0x7e4b 0x91a3 0x8f8 0x7fdf 0x916f 0x93d 0x8174 0x9127 0x960 0x8308 0x90d4 0x96d 0x849c 0x908f 0x996 0x8630 0x906f 0x9be 0x87c4 0x905c 0x9f8 0x8958 0x904c 0xa4e 0x8aec 0x9039 0xab3 0x8c81 0x901d 0xb1e 0x8e15 0x8feb 0xbae 0x8fa9 0x8f15 0xc03 0x913d 0x8d8a 0xc9a 0x92d1 0x8b60 0xd9a 0x9465 0x887a 0xf1f 0x95f9 0x845f 0x1140 0x978e 0x7a1c 0x22ed 0x9922 0x7044 0x133d 0x9ab6 0x7044 0x133d 0x9c4a 0x7044 0x133d>;
				battery0_profile_t2_num = <0x64>;
				battery0_profile_t3 = <0x0 0xa8fc 0xd16 0x194 0xa84a 0xd16 0x328 0xa7b1 0xd63 0x4bc 0xa728 0xda8 0x651 0xa6a8 0xdd1 0x7e5 0xa62d 0xdfa 0x979 0xa5bc 0xe22 0xb0d 0xa53e 0xe18 0xca1 0xa4c1 0xe10 0xe35 0xa44b 0xe1f 0xfc9 0xa3d9 0xe42 0x115e 0xa366 0xe42 0x12f2 0xa2fc 0xe54 0x1486 0xa28d 0xe69 0x161a 0xa21c 0xe74 0x17ae 0xa1ab 0xe74 0x1942 0xa13a 0xe74 0x1ad6 0xa0d0 0xe88 0x1c6b 0xa066 0xe8d 0x1dff 0xa000 0xea2 0x1f93 0x9fa3 0xed0 0x2127 0x9f52 0xf0d 0x22bb 0x9ef9 0xf49 0x244f 0x9e93 0xf55 0x25e3 0x9e13 0xf4a 0x2778 0x9d7f 0xf2f 0x290c 0x9ce7 0xf06 0x2aa0 0x9c5b 0xedd 0x2c34 0x9bf5 0xefc 0x2dc8 0x9b9e 0xf24 0x2f5c 0x9b54 0xf55 0x30f0 0x9b12 0xf87 0x3285 0x9ac9 0xf87 0x3419 0x9a79 0xf87 0x35ad 0x9a15 0xf79 0x3741 0x99a7 0xf51 0x38d5 0x9934 0xf0f 0x3a69 0x98bb 0xebf 0x3bfd 0x984a 0xe96 0x3d92 0x97eb 0xe6e 0x3f26 0x9797 0xe66 0x40ba 0x9748 0xe74 0x424e 0x9700 0xe73 0x43e2 0x96c0 0xe5f 0x4576 0x9685 0xe7d 0x470a 0x964c 0xe8d 0x489f 0x9616 0xe9c 0x4a33 0x95e5 0xec2 0x4bc7 0x95b5 0xed6 0x4d5b 0x9584 0xeea 0x4eef 0x9559 0xf0c 0x5083 0x952d 0xf2c 0x5217 0x9500 0xf44 0x53ab 0x94df 0xf6d 0x5540 0x94b7 0xf82 0x56d4 0x9494 0xfa5 0x5868 0x9470 0xfc3 0x59fc 0x944c 0xfdd 0x5b90 0x9433 0x1005 0x5d24 0x941b 0x102d 0x5eb8 0x9409 0x1066 0x604d 0x93f5 0x1097 0x61e1 0x93df 0x10c0 0x6375 0x93cf 0x10e8 0x6509 0x93bf 0x1111 0x669d 0x93ae 0x115b 0x6831 0x939e 0x11b8 0x69c5 0x938b 0x120e 0x6b5a 0x9372 0x1248 0x6cee 0x9352 0x1271 0x6e82 0x932a 0x1287 0x7016 0x9307 0x12c3 0x71aa 0x92e0 0x1314 0x733e 0x92af 0x1361 0x74d2 0x927e 0x139f 0x7667 0x924d 0x1416 0x77fb 0x920b 0x1481 0x798f 0x91c6 0x14e6 0x7b23 0x9186 0x1555 0x7cb7 0x9144 0x15e3 0x7e4b 0x90ec 0x1670 0x7fdf 0x90a6 0x171d 0x8174 0x9072 0x17ca 0x8308 0x9051 0x188f 0x849c 0x9040 0x1998 0x8630 0x9027 0x1ab2 0x87c4 0x9008 0x1c13 0x8958 0x8fcf 0x1da4 0x8aec 0x8f3f 0x1f54 0x8c81 0x8e18 0x2125 0x8e15 0x8c1b 0x236f 0x8fa9 0x8950 0x2703 0x913d 0x853c 0x2ca1 0x92d1 0x7eb5 0x3132 0x9465 0x72a6 0x17ed 0x95f9 0x72a6 0x17ed 0x978e 0x72a6 0x17ed 0x9922 0x72a6 0x17ed 0x9ab6 0x72a6 0x17ed 0x9c4a 0x72a6 0x17ed>;
				battery0_profile_t3_num = <0x64>;
				battery0_profile_t4 = <0x0 0xa8ac 0xf55 0x194 0xa7ea 0xf55 0x328 0xa74d 0xfc1 0x4bc 0xa6cb 0xeb4 0x651 0xa651 0xd5c 0x7e5 0xa5c9 0xe82 0x979 0xa550 0xf38 0xb0d 0xa4dd 0xfcc 0xca1 0xa467 0x1035 0xe35 0xa3ee 0x107e 0xfc9 0xa376 0x10b3 0x115e 0xa304 0x10b3 0x12f2 0xa293 0x10e9 0x1486 0xa21d 0x10fe 0x161a 0xa1aa 0x1117 0x17ae 0xa141 0x1145 0x1942 0xa0d8 0x1131 0x1ad6 0xa067 0x10f7 0x1c6b 0xa002 0x10f3 0x1dff 0x9fa4 0x111a 0x1f93 0x9f4d 0x1161 0x2127 0x9efa 0x11c6 0x22bb 0x9e89 0x11b1 0x244f 0x9e05 0x118d 0x25e3 0x9d58 0x1139 0x2778 0x9ca0 0x1104 0x290c 0x9c10 0x1162 0x2aa0 0x9b96 0x1162 0x2c34 0x9b3f 0x1184 0x2dc8 0x9aee 0x11ac 0x2f5c 0x9a8f 0x11b8 0x30f0 0x9a2a 0x11c4 0x3285 0x9a5a 0x1359 0x3419 0x9a10 0x109e 0x35ad 0x99a1 0x1045 0x3741 0x9924 0x1145 0x38d5 0x98a6 0x1214 0x3a69 0x9835 0x12a1 0x3bfd 0x97db 0x126d 0x3d92 0x9788 0x1296 0x3f26 0x973b 0x1285 0x40ba 0x96f4 0x1234 0x424e 0x96b3 0x125d 0x43e2 0x9671 0x12d9 0x4576 0x9637 0x1332 0x470a 0x9603 0x136d 0x489f 0x95d0 0x1395 0x4a33 0x9599 0x13b1 0x4bc7 0x9570 0x134c 0x4d5b 0x9541 0x134e 0x4eef 0x9515 0x1356 0x5083 0x94f0 0x135e 0x5217 0x94ce 0x136c 0x53ab 0x94a6 0x1358 0x5540 0x947d 0x1369 0x56d4 0x945a 0x137d 0x5868 0x943d 0x139a 0x59fc 0x9425 0x13c3 0x5b90 0x940d 0x13eb 0x5d24 0x93fc 0x143b 0x5eb8 0x93ec 0x147e 0x604d 0x93db 0x14b0 0x61e1 0x93cb 0x14df 0x6375 0x93bb 0x151c 0x6509 0x93ab 0x156d 0x669d 0x939b 0x15ce 0x6831 0x9386 0x161c 0x69c5 0x936e 0x1659 0x6b5a 0x9355 0x1697 0x6cee 0x9334 0x16e8 0x6e82 0x9306 0x1727 0x7016 0x92db 0x177e 0x71aa 0x92b2 0x180a 0x733e 0x9289 0x18e7 0x74d2 0x9258 0x1a2a 0x7667 0x9211 0x1aec 0x77fb 0x91ce 0x1be6 0x798f 0x9190 0x1cd6 0x7b23 0x9151 0x1da6 0x7cb7 0x9101 0x1ec1 0x7e4b 0x90a8 0x1f78 0x7fdf 0x9073 0x206b 0x8174 0x9053 0x21da 0x8308 0x903b 0x2372 0x849c 0x9023 0x2487 0x8630 0x900a 0x26c8 0x87c4 0x8fde 0x28ef 0x8958 0x8f5b 0x2b10 0x8aec 0x8e45 0x2d9e 0x8c81 0x8c6e 0x310a 0x8e15 0x89d8 0x3539 0x8fa9 0x8607 0x3af0 0x913d 0x8021 0x38c3 0x92d1 0x740e 0x1aa9 0x9465 0x740e 0x1aa9 0x95f9 0x740e 0x1aa9 0x978e 0x740e 0x1aa9 0x9922 0x740e 0x1aa9 0x9ab6 0x740e 0x1aa9 0x9c4a 0x740e 0x1aa9>;
				battery0_profile_t4_num = <0x64>;
				battery1_profile_t0 = <0x0 0xaab4 0x401 0x199 0xaa18 0x401 0x333 0xa983 0x3f1 0x4cc 0xa8fc 0x3e8 0x665 0xa883 0x3f7 0x7fe 0xa80e 0x414 0x998 0xa78b 0x3eb 0xb31 0xa70f 0x3e8 0xcca 0xa69a 0x3f6 0xe64 0xa623 0x401 0xffd 0xa5a8 0x401 0x1196 0xa536 0x402 0x1330 0xa4c3 0x417 0x14c9 0xa451 0x409 0x1662 0xa3d9 0x401 0x17fb 0xa361 0x3f9 0x1995 0xa2f0 0x3ec 0x1b2e 0xa283 0x400 0x1cc7 0xa211 0x401 0x1e61 0xa1a4 0x410 0x1ffa 0xa129 0x40f 0x2193 0xa0a7 0x40e 0x232c 0xa03d 0x431 0x24c6 0x9fd0 0x41c 0x265f 0x9f6d 0x41a 0x27f8 0x9f16 0x41a 0x2992 0x9ebc 0x423 0x2b2b 0x9e5a 0x42e 0x2cc4 0x9df8 0x41a 0x2e5d 0x9d94 0x41a 0x2ff7 0x9d38 0x42a 0x3190 0x9cd9 0x433 0x3329 0x9c7d 0x43a 0x34c3 0x9c2a 0x449 0x365c 0x9bcf 0x435 0x37f5 0x9b75 0x459 0x398f 0x9b1a 0x465 0x3b28 0x9ac3 0x46f 0x3cc1 0x9a76 0x484 0x3e5a 0x9a33 0x498 0x3ff4 0x99d9 0x4ad 0x418d 0x996b 0x49f 0x4326 0x98ee 0x465 0x44c0 0x9870 0x423 0x4659 0x9801 0x401 0x47f2 0x97a7 0x401 0x498b 0x9764 0x415 0x4b25 0x9723 0x41a 0x4cbe 0x96e1 0x40f 0x4e57 0x96a2 0x401 0x4ff1 0x966a 0x401 0x518a 0x9638 0x401 0x5323 0x95ff 0x401 0x54bd 0x95cb 0x401 0x5656 0x959e 0x401 0x57ef 0x9573 0x401 0x5988 0x9542 0x401 0x5b22 0x9519 0x401 0x5cbb 0x94ef 0x401 0x5e54 0x94cb 0x401 0x5fee 0x94aa 0x410 0x6187 0x9488 0x430 0x6320 0x945f 0x41c 0x64b9 0x9445 0x42d 0x6653 0x93e1 0x424 0x67ec 0x93bf 0x42e 0x6985 0x93e7 0x44c 0x6b1f 0x93ce 0x44c 0x6cb8 0x93a5 0x44c 0x6e51 0x9375 0x43b 0x6feb 0x932f 0x419 0x7184 0x92e3 0x409 0x731d 0x92a6 0x41e 0x74b6 0x927d 0x432 0x7650 0x9244 0x40b 0x77e9 0x9217 0x410 0x7982 0x91ea 0x40f 0x7b1c 0x91b2 0x401 0x7cb5 0x9177 0x403 0x7e4e 0x916f 0x418 0x7fe7 0x9151 0x42c 0x8181 0x9120 0x425 0x831a 0x90e3 0x408 0x84b3 0x90a5 0x3f1 0x864d 0x9073 0x41b 0x87e6 0x9039 0x42f 0x897f 0x8fec 0x412 0x8b18 0x8fb2 0x3f5 0x8cb2 0x8f98 0x3fe 0x8e4b 0x8f96 0x436 0x8fe4 0x8f85 0x44a 0x917e 0x8f75 0x472 0x9317 0x8f4d 0x49b 0x94b0 0x8ec2 0x491 0x964a 0x8da4 0x470 0x97e3 0x8be8 0x498 0x997c 0x898a 0x4ad 0x9b15 0x8637 0x505 0x9caf 0x8051 0x720 0x9e48 0x7594 0x1f72>;
				battery1_profile_t0_num = <0x64>;
				battery1_profile_t1 = <0x0 0xaa50 0x52d 0x199 0xa9b4 0x52d 0x333 0xa932 0x54d 0x4cc 0xa8b6 0x55f 0x665 0xa83a 0x55f 0x7fe 0xa7c0 0x55f 0x998 0xa74e 0x55f 0xb31 0xa6d3 0x55f 0xcca 0xa65e 0x55f 0xe64 0xa5ec 0x55f 0xffd 0xa576 0x55a 0x1196 0xa4fa 0x546 0x1330 0xa487 0x546 0x14c9 0xa415 0x546 0x1662 0xa3a2 0x546 0x17fb 0xa32f 0x53e 0x1995 0xa2bc 0x531 0x1b2e 0xa247 0x545 0x1cc7 0xa1dd 0x546 0x1e61 0xa172 0x555 0x1ffa 0xa108 0x55f 0x2193 0xa09d 0x55f 0x232c 0xa032 0x55d 0x24c6 0x9fbd 0x548 0x265f 0x9f59 0x546 0x27f8 0x9ef7 0x546 0x2992 0x9e98 0x558 0x2b2b 0x9e3c 0x578 0x2cc4 0x9dda 0x578 0x2e5d 0x9d6d 0x58d 0x2ff7 0x9d09 0x591 0x3190 0x9ca7 0x591 0x3329 0x9c4b 0x598 0x34c3 0x9bf9 0x5aa 0x365c 0x9ba7 0x5aa 0x37f5 0x9b55 0x5bd 0x398f 0x9b08 0x5e0 0x3b28 0x9ab9 0x5f5 0x3cc1 0x9a63 0x5f5 0x3e5a 0x9a01 0x5f4 0x3ff4 0x999e 0x5df 0x418d 0x9928 0x598 0x4326 0x98ab 0x552 0x44c0 0x9839 0x51c 0x4659 0x97d9 0x4f3 0x47f2 0x977f 0x4ca 0x498b 0x973c 0x4dd 0x4b25 0x96fb 0x4e2 0x4cbe 0x96bd 0x4e2 0x4e57 0x9686 0x4e2 0x4ff1 0x9654 0x4e2 0x518a 0x961a 0x4e2 0x5323 0x95e8 0x4d0 0x54bd 0x95bd 0x4d7 0x5656 0x9593 0x4eb 0x57ef 0x9568 0x4fb 0x5988 0x9537 0x4fb 0x5b22 0x9516 0x4fb 0x5cbb 0x94ef 0x4fb 0x5e54 0x94c6 0x4fb 0x5fee 0x94a3 0x50a 0x6187 0x9489 0x52a 0x6320 0x9468 0x515 0x64b9 0x9447 0x527 0x6653 0x9426 0x52d 0x67ec 0x940a 0x52d 0x6985 0x93ef 0x52d 0x6b1f 0x93ce 0x52f 0x6cb8 0x93b5 0x543 0x6e51 0x9396 0x546 0x6feb 0x936b 0x51f 0x7184 0x933d 0x4fb 0x731d 0x9314 0x4f7 0x74b6 0x92ea 0x4e2 0x7650 0x92b9 0x4ce 0x77e9 0x9295 0x4d9 0x7982 0x9274 0x4ed 0x7b1c 0x9250 0x4f4 0x7cb5 0x9228 0x4e4 0x7e4e 0x9207 0x4f9 0x7fe7 0x91df 0x4fb 0x8181 0x91aa 0x4fb 0x831a 0x9171 0x4fb 0x84b3 0x913a 0x505 0x864d 0x9108 0x52d 0x87e6 0x90c7 0x52d 0x897f 0x9077 0x52d 0x8b18 0x903d 0x52d 0x8cb2 0x901e 0x535 0x8e4b 0x900f 0x550 0x8fe4 0x9006 0x58d 0x917e 0x8fef 0x5b8 0x9317 0x8fc5 0x5ef 0x94b0 0x8f46 0x618 0x964a 0x8e35 0x632 0x97e3 0x8c69 0x65e 0x997c 0x89ee 0x6b1 0x9b15 0x8665 0x76d 0x9caf 0x7fa6 0xee5 0x9e48 0x77ec 0x249f>;
				battery1_profile_t1_num = <0x64>;
				battery1_profile_t2 = <0x0 0xa96a 0xa0f 0x199 0xa8b6 0xa0f 0x333 0xa81b 0xa3f 0x4cc 0xa790 0xa66 0x665 0xa70e 0xa73 0x7fe 0xa68d 0xa73 0x998 0xa5ea 0xa73 0xb31 0xa573 0xa73 0xcca 0xa506 0xa65 0xe64 0xa49f 0xa5a 0xffd 0xa436 0xa60 0x1196 0xa3c4 0xa72 0x1330 0xa35a 0xa5d 0x14c9 0xa2e9 0xa5a 0x1662 0xa276 0xa4d 0x17fb 0xa206 0xa49 0x1995 0xa198 0xa56 0x1b2e 0xa125 0xa42 0x1cc7 0xa0bb 0xa55 0x1e61 0xa050 0xa4b 0x1ffa 0x9fea 0xa4c 0x2193 0x9f8c 0xa67 0x232c 0x9f38 0xa8e 0x24c6 0x9ede 0xaa3 0x265f 0x9e84 0xac9 0x27f8 0x9e14 0xabc 0x2992 0x9d96 0xa9c 0x2b2b 0x9d15 0xa83 0x2cc4 0x9c9a 0xa5a 0x2e5d 0x9c36 0xa6f 0x2ff7 0x9be7 0xa94 0x3190 0x9b98 0xa99 0x3329 0x9b4c 0xa9b 0x34c3 0x9b0a 0xac1 0x365c 0x9ac0 0xad5 0x37f5 0x9a67 0xac4 0x398f 0x9a06 0xaa1 0x3b28 0x999f 0xa78 0x3cc1 0x992e 0xa43 0x3e5a 0x98ac 0x9f2 0x3ff4 0x9839 0x9a0 0x418d 0x97d4 0x970 0x4326 0x9786 0x96d 0x44c0 0x973d 0x971 0x4659 0x96ef 0x960 0x47f2 0x96b6 0x960 0x498b 0x9674 0x960 0x4b25 0x963f 0x96f 0x4cbe 0x960e 0x984 0x4e57 0x95df 0x998 0x4ff1 0x95b4 0x9a9 0x518a 0x957a 0x994 0x5323 0x9550 0x9a4 0x54bd 0x9527 0x9b9 0x5656 0x94fe 0x9c4 0x57ef 0x94d7 0x9c9 0x5988 0x94b5 0x9de 0x5b22 0x9494 0x9f2 0x5cbb 0x9474 0xa06 0x5e54 0x9453 0xa0f 0x5fee 0x9432 0xa16 0x6187 0x9413 0xa28 0x6320 0x93f9 0xa28 0x64b9 0x93e1 0xa4f 0x6653 0x93c8 0xa69 0x67ec 0x93b0 0xa73 0x6985 0x9397 0xa79 0x6b1f 0x937f 0xa8e 0x6cb8 0x936e 0xab8 0x6e51 0x9357 0xad0 0x6feb 0x9334 0xaca 0x7184 0x930e 0xad7 0x731d 0x92ec 0xb11 0x74b6 0x92c3 0xb3a 0x7650 0x9299 0xb4f 0x77e9 0x9277 0xb93 0x7982 0x9251 0xbda 0x7b1c 0x9226 0xc1e 0x7cb5 0x91f3 0xc6e 0x7e4e 0x91b1 0xcab 0x7fe7 0x9176 0xd0f 0x8181 0x913c 0xd76 0x831a 0x90f8 0xdd2 0x84b3 0x90ac 0xe33 0x864d 0x9073 0xec2 0x87e6 0x9042 0xf3d 0x897f 0x9024 0x100e 0x8b18 0x9006 0x10fd 0x8cb2 0x8fdf 0x1212 0x8e4b 0x8fa5 0x1350 0x8fe4 0x8f3a 0x145a 0x917e 0x8e2e 0x153d 0x9317 0x8c84 0x1659 0x94b0 0x8a1f 0x1821 0x964a 0x86a0 0x1b03 0x97e3 0x8142 0x200e 0x997c 0x7364 0x19af 0x9b15 0x7364 0x19af 0x9caf 0x7364 0x19af 0x9e48 0x7364 0x19af>;
				battery1_profile_t2_num = <0x64>;
				battery1_profile_t3 = <0x0 0xa834 0x13d3 0x199 0xa757 0x13d3 0x333 0xa6a7 0x1452 0x4cc 0xa60a 0x14ca 0x665 0xa57b 0x150e 0x7fe 0xa4f8 0x1531 0x998 0xa475 0x1531 0xb31 0xa3f9 0x1544 0xcca 0xa384 0x154a 0xe64 0xa2f7 0x1540 0xffd 0xa259 0x1536 0x1196 0xa1e3 0x1549 0x1330 0xa169 0x1534 0x14c9 0xa0fb 0x1531 0x1662 0xa08c 0x1524 0x17fb 0xa01d 0x1518 0x1995 0x9fb6 0x151c 0x1b2e 0x9f62 0x1530 0x1cc7 0x9f09 0x1545 0x1e61 0x9ea8 0x1569 0x1ffa 0x9e4f 0x1571 0x2193 0x9dee 0x154a 0x232c 0x9d69 0x14fa 0x24c6 0x9cd3 0x14bb 0x265f 0x9c5c 0x14b4 0x27f8 0x9bfa 0x14c2 0x2992 0x9ba7 0x14d6 0x2b2b 0x9b5e 0x14eb 0x2cc4 0x9b14 0x14ff 0x2e5d 0x9ac9 0x1529 0x2ff7 0x9a7f 0x1531 0x3190 0x9a2c 0x1519 0x3329 0x99d2 0x1506 0x34c3 0x9974 0x150d 0x365c 0x9902 0x14bb 0x37f5 0x9896 0x148e 0x398f 0x982b 0x1456 0x3b28 0x97c3 0x1423 0x3cc1 0x9768 0x140b 0x3e5a 0x971e 0x141d 0x3ff4 0x96cc 0x1408 0x418d 0x9687 0x1405 0x4326 0x964b 0x141e 0x44c0 0x9614 0x143f 0x4659 0x95e1 0x1454 0x47f2 0x95a8 0x1468 0x498b 0x9576 0x1469 0x4b25 0x954b 0x1497 0x4cbe 0x951e 0x14bf 0x4e57 0x94ef 0x14d3 0x4ff1 0x94c6 0x14ea 0x518a 0x94a6 0x1513 0x5323 0x9485 0x153c 0x54bd 0x9464 0x1565 0x5656 0x9447 0x158e 0x57ef 0x942e 0x15b7 0x5988 0x9415 0x15e2 0x5b22 0x93fd 0x161f 0x5cbb 0x93f1 0x166d 0x5e54 0x93e0 0x169b 0x5fee 0x93ca 0x16c6 0x6187 0x93ba 0x1717 0x6320 0x93a9 0x1769 0x64b9 0x9391 0x17a9 0x6653 0x937e 0x1805 0x67ec 0x9366 0x187f 0x6985 0x9347 0x1909 0x6b1f 0x932e 0x1983 0x6cb8 0x930d 0x19e9 0x6e51 0x92e6 0x1a4f 0x6feb 0x92c2 0x1adb 0x7184 0x929a 0x1b70 0x731d 0x9269 0x1bf9 0x74b6 0x9237 0x1cb1 0x7650 0x9206 0x1d55 0x77e9 0x91cf 0x1e17 0x7982 0x9191 0x1ed9 0x7b1c 0x9150 0x1f99 0x7cb5 0x910e 0x2070 0x7e4e 0x90d4 0x217a 0x7fe7 0x90a2 0x22a9 0x8181 0x906c 0x23f7 0x831a 0x9036 0x2565 0x84b3 0x9005 0x26f7 0x864d 0x8fd4 0x28ba 0x87e6 0x8f89 0x2aaf 0x897f 0x8f1e 0x2cac 0x8b18 0x8e68 0x2e7c 0x8cb2 0x8d51 0x3014 0x8e4b 0x8bc3 0x3184 0x8fe4 0x897e 0x32f5 0x917e 0x85a7 0x35eb 0x9317 0x7f4c 0x36ab 0x94b0 0x74e0 0x1db0 0x964a 0x74e0 0x1db0 0x97e3 0x74e0 0x1db0 0x997c 0x74e0 0x1db0 0x9b15 0x74e0 0x1db0 0x9caf 0x74e0 0x1db0 0x9e48 0x74e0 0x1db0>;
				battery1_profile_t3_num = <0x64>;
				battery1_profile_t4 = <0x0 0xa7e4 0x1612 0x199 0xa6f7 0x1612 0x333 0xa649 0x16e1 0x4cc 0xa5b5 0x14d8 0x665 0xa52b 0x12b7 0x7fe 0xa4a9 0x14a7 0x998 0xa42e 0x15b1 0xb31 0xa3b3 0x165d 0xcca 0xa339 0x16e4 0xe64 0xa2c1 0x1756 0xffd 0xa24f 0x17a2 0x1196 0xa1e3 0x17a5 0x1330 0xa169 0x17e3 0x14c9 0xa0fb 0x17fe 0x1662 0xa091 0x1806 0x17fb 0xa02d 0x17fe 0x1995 0x9fd1 0x17e2 0x1b2e 0x9f6d 0x17a4 0x1cc7 0x9f1b 0x17ca 0x1e61 0x9ebc 0x17d4 0x1ffa 0x9e45 0x17b4 0x2193 0x9dbc 0x177c 0x232c 0x9d38 0x1753 0x24c6 0x9caa 0x172a 0x265f 0x9c1f 0x1725 0x27f8 0x9baf 0x1733 0x2992 0x9b57 0x1750 0x2b2b 0x9b0f 0x1779 0x2cc4 0x9ace 0x17a2 0x2e5d 0x9a9d 0x17a2 0x2ff7 0x9a51 0x17c3 0x3190 0x99fa 0x17f8 0x3329 0x999d 0x16d3 0x34c3 0x9936 0x13fb 0x365c 0x98b3 0x15d2 0x37f5 0x9837 0x1725 0x398f 0x97d3 0x1834 0x3b28 0x977c 0x188d 0x3cc1 0x9729 0x1873 0x3e5a 0x96d9 0x18de 0x3ff4 0x96a0 0x183a 0x418d 0x9652 0x1841 0x4326 0x9619 0x18ce 0x44c0 0x95ea 0x196b 0x4659 0x95b3 0x19af 0x47f2 0x9589 0x19af 0x498b 0x9558 0x1a12 0x4b25 0x9533 0x19c1 0x4cbe 0x950e 0x197d 0x4e57 0x94e5 0x197d 0x4ff1 0x94bd 0x197b 0x518a 0x949c 0x1966 0x5323 0x947b 0x1964 0x54bd 0x945a 0x1972 0x5656 0x943d 0x198f 0x57ef 0x9425 0x19b8 0x5988 0x940c 0x19e1 0x5b22 0x9404 0x1a20 0x5cbb 0x93f5 0x1a5d 0x5e54 0x93e4 0x1a9b 0x5fee 0x93d4 0x1ad1 0x6187 0x93c4 0x1b02 0x6320 0x93b3 0x1b69 0x64b9 0x939b 0x1be2 0x6653 0x9383 0x1c5c 0x67ec 0x936a 0x1ccf 0x6985 0x9351 0x1d3c 0x6b1f 0x9338 0x1db6 0x6cb8 0x930f 0x1e1c 0x6e51 0x92e6 0x1ea4 0x6feb 0x92bd 0x1f4d 0x7184 0x9294 0x2025 0x731d 0x926a 0x2153 0x74b6 0x9237 0x2333 0x7650 0x91fe 0x246b 0x77e9 0x91cb 0x25eb 0x7982 0x918d 0x2703 0x7b1c 0x914b 0x27f8 0x7cb5 0x9117 0x2995 0x7e4e 0x90c3 0x2a7a 0x7fe7 0x9080 0x2bb7 0x8181 0x9054 0x2d79 0x831a 0x9033 0x2ef9 0x84b3 0x9011 0x300c 0x864d 0x8fe8 0x31ce 0x87e6 0x8faf 0x32d8 0x897f 0x8f49 0x33b3 0x8b18 0x8e57 0x34b0 0x8cb2 0x8cad 0x360e 0x8e4b 0x8a41 0x37fd 0x8fe4 0x86b5 0x3b07 0x917e 0x80bc 0x3a32 0x9317 0x7562 0x22dd 0x94b0 0x7562 0x22dd 0x964a 0x7562 0x22dd 0x97e3 0x7562 0x22dd 0x997c 0x7562 0x22dd 0x9b15 0x7562 0x22dd 0x9caf 0x7562 0x22dd 0x9e48 0x7562 0x22dd>;
				battery1_profile_t4_num = <0x64>;
				battery2_profile_t0 = <0x0 0xab0e 0x339 0x144 0xaa5f 0x37a 0x287 0xa9bf 0x39d 0x3cb 0xa931 0x39d 0x50f 0xa8ae 0x38e 0x653 0xa82f 0x384 0x796 0xa7b4 0x384 0x8da 0xa739 0x384 0xa1e 0xa6c0 0x388 0xb62 0xa64b 0x399 0xca5 0xa5d2 0x39d 0xde9 0xa559 0x3a0 0xf2d 0xa4e8 0x3b1 0x1071 0xa471 0x3ab 0x11b4 0xa3f7 0x39b 0x12f8 0xa382 0x38b 0x143c 0xa311 0x38d 0x1580 0xa2a3 0x39d 0x16c3 0xa235 0x39d 0x1807 0xa1c7 0x39d 0x194b 0xa159 0x39d 0x1a8e 0xa0e9 0x3ad 0x1bd2 0xa07c 0x3b6 0x1d16 0xa015 0x3b6 0x1e5a 0x9fa8 0x3b6 0x1f9d 0x9f3e 0x3bc 0x20e1 0x9edd 0x3cc 0x2225 0x9e7c 0x3cf 0x2369 0x9e1b 0x3d3 0x24ac 0x9db9 0x3e3 0x25f0 0x9d5d 0x3e8 0x2734 0x9d02 0x3eb 0x2878 0x9ca8 0x3fb 0x29bb 0x9c4d 0x401 0x2aff 0x9bf3 0x402 0x2c43 0x9b9d 0x413 0x2d87 0x9b4c 0x42c 0x2eca 0x9afe 0x44d 0x300e 0x9ab0 0x46d 0x3152 0x9a60 0x47e 0x3295 0x9a0b 0x47e 0x33d9 0x99b7 0x49c 0x351d 0x9954 0x490 0x3661 0x98d9 0x43f 0x37a4 0x9858 0x3fc 0x38e8 0x97e3 0x3c5 0x3a2c 0x9788 0x3a5 0x3b70 0x973b 0x39d 0x3cb3 0x96f4 0x399 0x3df7 0x96b3 0x389 0x3f3b 0x9677 0x384 0x407f 0x963e 0x387 0x41c2 0x960a 0x397 0x4306 0x95de 0x3a7 0x444a 0x95b7 0x3b5 0x458e 0x9583 0x3a5 0x46d1 0x9552 0x3a5 0x4815 0x9525 0x3b6 0x4959 0x94fe 0x3b6 0x4a9d 0x94d7 0x3bd 0x4be0 0x94af 0x3ce 0x4d24 0x948e 0x3de 0x4e68 0x946b 0x3e8 0x4fab 0x9445 0x3e8 0x50ef 0x9428 0x3f5 0x5233 0x940f 0x40a 0x5377 0x93f5 0x42b 0x54ba 0x93d6 0x427 0x55fe 0x93b6 0x41d 0x5742 0x9395 0x42d 0x5886 0x9357 0x3fe 0x59c9 0x930a 0x3b4 0x5b0d 0x92bc 0x3a4 0x5c51 0x9280 0x3a6 0x5d95 0x9252 0x3b6 0x5ed8 0x9224 0x3b6 0x601c 0x91f4 0x3ae 0x6160 0x91c0 0x39e 0x62a4 0x919f 0x3ad 0x63e7 0x917c 0x3b6 0x652b 0x9155 0x3b6 0x666f 0x9127 0x3c5 0x67b2 0x90f3 0x3c9 0x68f6 0x90b9 0x3b8 0x6a3a 0x907e 0x3c4 0x6b7e 0x903e 0x3ca 0x6cc1 0x8ff7 0x3b9 0x6e05 0x8fba 0x3a9 0x6f49 0x8f8b 0x39d 0x708d 0x8f7e 0x39d 0x71d0 0x8f75 0x3c1 0x7314 0x8f69 0x3f4 0x7458 0x8f4f 0x426 0x759c 0x8edb 0x427 0x76df 0x8e0d 0x41d 0x7823 0x8c4f 0x42d 0x7967 0x89f5 0x467 0x7aab 0x8703 0x4d2 0x7bee 0x81ad 0x626 0x7d32 0x7738 0x514>;
				battery2_profile_t0_num = <0x64>;
				battery2_profile_t1 = <0x0 0xaab4 0x47e 0x144 0xaa19 0x4df 0x287 0xa989 0x514 0x3cb 0xa908 0x514 0x50f 0xa886 0x505 0x653 0xa806 0x501 0x796 0xa788 0x512 0x8da 0xa70d 0x4f8 0xa1e 0xa694 0x4e2 0xb62 0xa61f 0x4e2 0xca5 0xa5ab 0x4ee 0xde9 0xa538 0x4ff 0xf2d 0xa4ca 0x50f 0x1071 0xa453 0x509 0x11b4 0xa3d9 0x4fb 0x12f8 0xa369 0x4fb 0x143c 0xa2f6 0x4fb 0x1580 0xa282 0x4fb 0x16c3 0xa214 0x4fb 0x1807 0xa1a6 0x4fb 0x194b 0xa138 0x4fb 0x1a8e 0xa0d0 0x50b 0x1bd2 0xa066 0x514 0x1d16 0x9ff8 0x514 0x1e5a 0x9f93 0x532 0x1f9d 0x9f31 0x546 0x20e1 0x9ed0 0x546 0x2225 0x9e74 0x561 0x2369 0x9e14 0x573 0x24ac 0x9da6 0x563 0x25f0 0x9d3d 0x56b 0x2734 0x9cd6 0x57b 0x2878 0x9c75 0x58b 0x29bb 0x9c20 0x5a7 0x2aff 0x9bd0 0x5c5 0x2c43 0x9b7c 0x5d6 0x2d87 0x9b2f 0x5ef 0x2eca 0x9ae8 0x610 0x300e 0x9a9a 0x630 0x3152 0x9a46 0x62f 0x3295 0x99eb 0x60f 0x33d9 0x9984 0x5ef 0x351d 0x9914 0x5ba 0x3661 0x9899 0x569 0x37a4 0x9822 0x516 0x38e8 0x97b7 0x4d6 0x3a2c 0x9763 0x4b6 0x3b70 0x971f 0x4b0 0x3cb3 0x96e0 0x4b0 0x3df7 0x96a6 0x4b0 0x3f3b 0x966b 0x4a4 0x407f 0x9632 0x49a 0x41c2 0x95ff 0x4aa 0x4306 0x95cf 0x4b0 0x444a 0x95a2 0x4b0 0x458e 0x9574 0x4b0 0x46d1 0x954a 0x4b9 0x4815 0x9524 0x4c9 0x4959 0x94fc 0x4c9 0x4a9d 0x94d5 0x4d1 0x4be0 0x94ae 0x4e1 0x4d24 0x948d 0x4e2 0x4e68 0x946f 0x4ef 0x4fab 0x9456 0x510 0x50ef 0x943c 0x522 0x5233 0x9420 0x52d 0x5377 0x93ff 0x52d 0x54ba 0x93e4 0x52d 0x55fe 0x93c9 0x52d 0x5742 0x93a8 0x52d 0x5886 0x9383 0x522 0x59c9 0x935c 0x50f 0x5b0d 0x932e 0x4ef 0x5c51 0x9301 0x4d8 0x5d95 0x92d4 0x4c7 0x5ed8 0x92a6 0x4a7 0x601c 0x927c 0x49f 0x6160 0x9254 0x4b0 0x62a4 0x9234 0x4c0 0x63e7 0x9213 0x4d0 0x652b 0x91f3 0x4e0 0x666f 0x91c1 0x4e2 0x67b2 0x9189 0x4dc 0x68f6 0x9148 0x4cc 0x6a3a 0x9112 0x4e3 0x6b7e 0x90d7 0x4fb 0x6cc1 0x9089 0x4fb 0x6e05 0x904e 0x4fb 0x6f49 0x9020 0x4fb 0x708d 0x900d 0x4fb 0x71d0 0x9002 0x52f 0x7314 0x8ff9 0x57e 0x7458 0x8fd8 0x5c0 0x759c 0x8f65 0x5e5 0x76df 0x8eab 0x5f6 0x7823 0x8cbf 0x617 0x7967 0x8a47 0x676 0x7aab 0x873e 0x718 0x7bee 0x8073 0xdd4 0x7d32 0x77ba 0x6a4>;
				battery2_profile_t1_num = <0x64>;
				battery2_profile_t2 = <0x0 0xaa1e 0x8b1 0x144 0xa96f 0x860 0x287 0xa8d2 0x843 0x3cb 0xa84a 0x863 0x50f 0xa7c8 0x857 0x653 0xa748 0x853 0x796 0xa6ca 0x864 0x8da 0xa655 0x866 0xa1e 0xa5de 0x85c 0xb62 0xa563 0x83c 0xca5 0xa4ed 0x840 0xde9 0xa47a 0x84d 0xf2d 0xa40c 0x84d 0x1071 0xa399 0x842 0x11b4 0xa325 0x832 0x12f8 0xa2b0 0x822 0x143c 0xa242 0x82e 0x1580 0xa1d8 0x84e 0x16c3 0xa16a 0x85e 0x1807 0xa0fc 0x866 0x194b 0xa08e 0x866 0x1a8e 0xa026 0x866 0x1bd2 0x9fc1 0x86d 0x1d16 0x9f60 0x87d 0x1e5a 0x9f0b 0x89c 0x1f9d 0x9eb4 0x8c2 0x20e1 0x9e5a 0x8f3 0x2225 0x9de0 0x8e2 0x2369 0x9d5c 0x8c2 0x24ac 0x9cd4 0x8a1 0x25f0 0x9c68 0x8a4 0x2734 0x9c0b 0x8b4 0x2878 0x9bbd 0x8c4 0x29bb 0x9b77 0x8de 0x2aff 0x9b36 0x8fd 0x2c43 0x9aed 0x90e 0x2d87 0x9a9e 0x915 0x2eca 0x9a4a 0x915 0x300e 0x99ef 0x904 0x3152 0x998b 0x8dd 0x3295 0x991d 0x89c 0x33d9 0x98af 0x84c 0x351d 0x9841 0x7fb 0x3661 0x97d3 0x7aa 0x37a4 0x9780 0x783 0x38e8 0x9734 0x76c 0x3a2c 0x96ed 0x76c 0x3b70 0x96b0 0x760 0x3cb3 0x9675 0x753 0x3df7 0x963a 0x753 0x3f3b 0x9604 0x753 0x407f 0x95d2 0x758 0x41c2 0x95ab 0x778 0x4306 0x9580 0x785 0x444a 0x9553 0x786 0x458e 0x952d 0x796 0x46d1 0x9506 0x79e 0x4815 0x94df 0x79e 0x4959 0x94b8 0x7ae 0x4a9d 0x9494 0x7be 0x4be0 0x9474 0x7ce 0x4d24 0x9458 0x7df 0x4e68 0x943c 0x7e9 0x4fab 0x941b 0x7e9 0x50ef 0x9400 0x7f6 0x5233 0x93e7 0x802 0x5377 0x93cd 0x802 0x54ba 0x93b3 0x802 0x55fe 0x939a 0x805 0x5742 0x9387 0x815 0x5886 0x936f 0x81b 0x59c9 0x9354 0x81b 0x5b0d 0x9333 0x81b 0x5c51 0x930f 0x81b 0x5d95 0x92e8 0x81b 0x5ed8 0x92c1 0x81b 0x601c 0x929a 0x82b 0x6160 0x9273 0x84c 0x62a4 0x9253 0x88b 0x63e7 0x9225 0x8b1 0x652b 0x91e4 0x8b1 0x666f 0x91af 0x8ea 0x67b2 0x9179 0x92a 0x68f6 0x913f 0x96b 0x6a3a 0x90f4 0x9a0 0x6b7e 0x90a8 0x9d1 0x6cc1 0x9068 0xa02 0x6e05 0x904c 0xa6f 0x6f49 0x903e 0xafd 0x708d 0x902a 0xbaf 0x71d0 0x9006 0xc8c 0x7314 0x8fca 0xd89 0x7458 0x8f28 0xecd 0x759c 0x8dc7 0xfb3 0x76df 0x8bd0 0x1064 0x7823 0x88b4 0x12cc 0x7967 0x8404 0x1668 0x7aab 0x7bcd 0x10cd 0x7bee 0x78e6 0x992 0x7d32 0x78e6 0x992>;
				battery2_profile_t2_num = <0x64>;
				battery2_profile_t3 = <0x0 0xa9b0 0xf23 0x144 0xa873 0xf13 0x287 0xa74a 0x100c 0x3cb 0xa63a 0x1243 0x50f 0xa58f 0x1335 0x653 0xa4f6 0x13c6 0x796 0xa46e 0x13e6 0x8da 0xa3f1 0x13df 0xa1e 0xa379 0x13e5 0xb62 0xa30b 0x1426 0xca5 0xa299 0x1443 0xde9 0xa225 0x1450 0xf2d 0xa1b7 0x1450 0x1071 0xa149 0x145a 0x11b4 0xa0dc 0x1469 0x12f8 0xa074 0x1469 0x143c 0xa014 0x1484 0x1580 0x9fb9 0x14b5 0x16c3 0x9f6b 0x1506 0x1807 0x9f12 0x1531 0x194b 0x9eaa 0x1531 0x1a8e 0x9e1f 0x1504 0x1bd2 0x9d8b 0x14c7 0x1d16 0x9cf0 0x1477 0x1e5a 0x9c70 0x144e 0x1f9d 0x9bfc 0x143c 0x20e1 0x9b9b 0x144c 0x2225 0x9b43 0x1444 0x2369 0x9af2 0x1437 0x24ac 0x9aab 0x1437 0x25f0 0x9a5f 0x1442 0x2734 0x9a10 0x144b 0x2878 0x99b5 0x141a 0x29bb 0x9953 0x13f3 0x2aff 0x98ec 0x13d2 0x2c43 0x988b 0x13a1 0x2d87 0x982a 0x1361 0x2eca 0x97c9 0x1310 0x300e 0x9773 0x12ed 0x3152 0x9727 0x12e6 0x3295 0x96e6 0x1306 0x33d9 0x96a5 0x12fd 0x351d 0x9667 0x12fc 0x3661 0x962c 0x131c 0x37a4 0x95f7 0x1324 0x38e8 0x95c6 0x132e 0x3a2c 0x959f 0x135f 0x3b70 0x956f 0x1364 0x3cb3 0x953d 0x135e 0x3df7 0x9516 0x139f 0x3f3b 0x94f0 0x13c3 0x407f 0x94c9 0x13d3 0x41c2 0x94a9 0x13d3 0x4306 0x9485 0x13e3 0x444a 0x945e 0x1403 0x458e 0x9444 0x1433 0x46d1 0x942a 0x145d 0x4815 0x9410 0x147d 0x4959 0x93fb 0x14b9 0x4a9d 0x93e8 0x14eb 0x4be0 0x93d5 0x14fb 0x4d24 0x93c1 0x1524 0x4e68 0x93ae 0x1558 0x4fab 0x939a 0x1599 0x50ef 0x938b 0x15e6 0x5233 0x937c 0x1638 0x5377 0x9362 0x1689 0x54ba 0x9348 0x16da 0x55fe 0x932e 0x172b 0x5742 0x9314 0x177c 0x5886 0x92f0 0x17e7 0x59c9 0x92c3 0x1868 0x5b0d 0x9295 0x18da 0x5c51 0x9265 0x194b 0x5d95 0x9231 0x19bc 0x5ed8 0x91f8 0x1a68 0x601c 0x91bb 0x1b14 0x6160 0x917a 0x1bb6 0x62a4 0x913a 0x1c8c 0x63e7 0x90fb 0x1d7b 0x652b 0x90c0 0x1e8f 0x666f 0x9094 0x1fc5 0x67b2 0x906d 0x211f 0x68f6 0x9046 0x22e4 0x6a3a 0x9017 0x24f1 0x6b7e 0x8fdc 0x2735 0x6cc1 0x8f4d 0x2a0e 0x6e05 0x8e3a 0x2cb2 0x6f49 0x8cb5 0x2f29 0x708d 0x8a2f 0x3203 0x71d0 0x86e8 0x2c71 0x7314 0x81f8 0x203f 0x7458 0x8020 0x1b8a 0x759c 0x8020 0x1b8a 0x76df 0x8020 0x1b8a 0x7823 0x8020 0x1b8a 0x7967 0x8020 0x1b8a 0x7aab 0x8020 0x1b8a 0x7bee 0x8020 0x1b8a 0x7d32 0x8020 0x1b8a>;
				battery2_profile_t3_num = <0x64>;
				battery2_profile_t4 = <0x0 0xa906 0x22f6 0x144 0xa844 0x2357 0x287 0xa784 0x23b1 0x3cb 0xa6c9 0x2402 0x50f 0xa5fd 0x23fa 0x653 0xa509 0x240a 0x796 0xa3d9 0x244a 0x8da 0xa2e0 0x25c9 0xa1e 0xa20c 0x2715 0xb62 0xa177 0x2776 0xca5 0xa0f1 0x274f 0xde9 0xa077 0x2709 0xf2d 0xa016 0x26e9 0x1071 0x9fb0 0x26bd 0x11b4 0x9f46 0x2688 0x12f8 0x9ec8 0x2636 0x143c 0x9e3c 0x25c6 0x1580 0x9da7 0x2545 0x16c3 0x9d12 0x24c3 0x1807 0x9c8b 0x245b 0x194b 0x9c10 0x240a 0x1a8e 0x9bae 0x23f9 0x1bd2 0x9b50 0x23e9 0x1d16 0x9af6 0x23d9 0x1e5a 0x9a9b 0x23c9 0x1f9d 0x9a3e 0x23b3 0x20e1 0x99dd 0x2392 0x2225 0x996f 0x2349 0x2369 0x9900 0x22f7 0x24ac 0x9892 0x22a6 0x25f0 0x9832 0x2286 0x2734 0x97d9 0x2272 0x2878 0x9785 0x2252 0x29bb 0x9739 0x2247 0x2aff 0x96f2 0x2247 0x2c43 0x96b0 0x2247 0x2d87 0x9673 0x2247 0x2eca 0x9639 0x2249 0x300e 0x9605 0x2269 0x3152 0x95d1 0x2279 0x3295 0x959e 0x2279 0x33d9 0x9576 0x22a8 0x351d 0x954d 0x22c4 0x3661 0x9520 0x22c4 0x37a4 0x94f7 0x22e1 0x38e8 0x94d2 0x2308 0x3a2c 0x94b2 0x2338 0x3b70 0x9494 0x2341 0x3cb3 0x9478 0x2366 0x3df7 0x945e 0x23b7 0x3f3b 0x9444 0x23f9 0x407f 0x942d 0x2440 0x41c2 0x9419 0x2491 0x4306 0x9406 0x24e2 0x444a 0x93f1 0x2533 0x458e 0x93d7 0x2584 0x46d1 0x93c2 0x25f9 0x4815 0x93ac 0x2677 0x4959 0x938b 0x26e8 0x4a9d 0x936b 0x2771 0x4be0 0x934a 0x2809 0x4d24 0x9329 0x28bb 0x4e68 0x9301 0x295a 0x4fab 0x92d4 0x29ee 0x50ef 0x92a0 0x2ab1 0x5233 0x926c 0x2b73 0x5377 0x9238 0x2c35 0x54ba 0x91fe 0x2cf7 0x55fe 0x91c4 0x2dc0 0x5742 0x918a 0x2e93 0x5886 0x914e 0x2f77 0x59c9 0x9116 0x3063 0x5b0d 0x90e2 0x3155 0x5c51 0x90ae 0x3262 0x5d95 0x907a 0x337a 0x5ed8 0x9046 0x349d 0x601c 0x9000 0x35d8 0x6160 0x8fa5 0x3713 0x62a4 0x8f11 0x3826 0x63e7 0x8e11 0x38fc 0x652b 0x8cc3 0x395b 0x666f 0x8aa9 0x35b8 0x67b2 0x876b 0x2dac 0x68f6 0x81f5 0x201f 0x6a3a 0x811a 0x1e78 0x6b7e 0x811a 0x1e78 0x6cc1 0x811a 0x1e78 0x6e05 0x811a 0x1e78 0x6f49 0x811a 0x1e78 0x708d 0x811a 0x1e78 0x71d0 0x811a 0x1e78 0x7314 0x811a 0x1e78 0x7458 0x811a 0x1e78 0x759c 0x811a 0x1e78 0x76df 0x811a 0x1e78 0x7823 0x811a 0x1e78 0x7967 0x811a 0x1e78 0x7aab 0x811a 0x1e78 0x7bee 0x811a 0x1e78 0x7d32 0x811a 0x1e78>;
				battery2_profile_t4_num = <0x64>;
				battery3_profile_t0 = <0x0 0xab18 0x36b 0x13a 0xaa94 0x36b 0x274 0xaa13 0x365 0x3af 0xa995 0x355 0x4e9 0xa921 0x35f 0x623 0xa8ae 0x367 0x75d 0xa830 0x358 0x898 0xa7ba 0x35c 0x9d2 0xa749 0x36c 0xb0c 0xa6d1 0x37b 0xc46 0xa65a 0x384 0xd81 0xa5e2 0x384 0xebb 0xa566 0x376 0xff5 0xa4eb 0x36f 0x112f 0xa47a 0x37f 0x126a 0xa405 0x379 0x13a4 0xa38e 0x36c 0x14de 0xa31d 0x37c 0x1618 0xa2ac 0x384 0x1753 0xa23b 0x384 0x188d 0xa1c9 0x384 0x19c7 0xa15a 0x389 0x1b01 0xa0ef 0x399 0x1c3c 0xa085 0x39d 0x1d76 0xa01a 0x39d 0x1eb0 0x9faf 0x39d 0x1fea 0x9f44 0x39d 0x2125 0x9ed9 0x39d 0x225f 0x9e74 0x3ac 0x2399 0x9e12 0x3bc 0x24d3 0x9db4 0x3cb 0x260e 0x9d51 0x3cf 0x2748 0x9cee 0x3d2 0x2882 0x9c96 0x3e2 0x29bc 0x9c3e 0x3f1 0x2af6 0x9be6 0x401 0x2c31 0x9b8e 0x411 0x2d6b 0x9b39 0x42d 0x2ea5 0x9ae7 0x45c 0x2fdf 0x9a86 0x465 0x311a 0x9a1f 0x45e 0x3254 0x99ae 0x43f 0x338e 0x9935 0x40b 0x34c8 0x98b8 0x3ce 0x3603 0x9853 0x3ae 0x373d 0x97f7 0x396 0x3877 0x97a6 0x386 0x39b1 0x975f 0x377 0x3aec 0x971b 0x36f 0x3c26 0x96dc 0x37f 0x3d60 0x96a2 0x384 0x3e9a 0x9669 0x383 0x3fd5 0x9631 0x373 0x410f 0x95fe 0x37a 0x4249 0x95d2 0x39a 0x4383 0x959b 0x381 0x44be 0x9568 0x375 0x45f8 0x9543 0x394 0x4732 0x9518 0x39d 0x486c 0x94ed 0x39f 0x49a7 0x94c7 0x3af 0x4ae1 0x94a2 0x3b6 0x4c1b 0x947c 0x3b6 0x4d55 0x9456 0x3b6 0x4e90 0x9435 0x3c1 0x4fca 0x941c 0x3e1 0x5104 0x93f9 0x3dc 0x523e 0x93d2 0x3d2 0x5378 0x93ad 0x3e2 0x54b3 0x9374 0x3cb 0x55ed 0x932e 0x39c 0x5727 0x92dc 0x37d 0x5861 0x929b 0x372 0x599c 0x926f 0x381 0x5ad6 0x923e 0x384 0x5c10 0x920d 0x388 0x5d4a 0x91e1 0x398 0x5e85 0x91b9 0x39d 0x5fbf 0x9193 0x39d 0x60f9 0x916e 0x39d 0x6233 0x9145 0x39d 0x636e 0x9119 0x39d 0x64a8 0x90dc 0x39d 0x65e2 0x909e 0x398 0x671c 0x905f 0x389 0x6857 0x9020 0x38f 0x6991 0x8fe2 0x39a 0x6acb 0x8fb0 0x37a 0x6c05 0x8f91 0x373 0x6d40 0x8f85 0x383 0x6e7a 0x8f7e 0x3b0 0x6fb4 0x8f6d 0x3df 0x70ee 0x8f48 0x40e 0x7229 0x8e9f 0x3eb 0x7363 0x8da2 0x3bd 0x749d 0x8bd1 0x3ec 0x75d7 0x8964 0x436 0x7712 0x867e 0x494 0x784c 0x8028 0x719 0x7986 0x7684 0x3e8>;
				battery3_profile_t0_num = <0x64>;
				battery3_profile_t1 = <0x0 0xaae6 0x4c9 0x13a 0xaa55 0x48a 0x274 0xa9d2 0x478 0x3af 0xa961 0x4a7 0x4e9 0xa8ea 0x4bd 0x623 0xa873 0x4c5 0x75d 0xa7fc 0x4b6 0x898 0xa780 0x4b0 0x9d2 0xa703 0x4b0 0xb0c 0xa68b 0x4b0 0xc46 0xa614 0x4b0 0xd81 0xa59c 0x4b0 0xebb 0xa525 0x4b0 0xff5 0xa4af 0x4b0 0x112f 0xa43e 0x4b0 0x126a 0xa3cd 0x4bb 0x13a4 0xa35c 0x4c9 0x14de 0xa2eb 0x4c9 0x1618 0xa277 0x4c1 0x1753 0xa1ff 0x4b1 0x188d 0xa193 0x4cc 0x19c7 0xa126 0x4e2 0x1b01 0xa0b5 0x4e2 0x1c3c 0xa049 0x4ed 0x1d76 0x9fdf 0x4fd 0x1eb0 0x9f7a 0x50d 0x1fea 0x9f1c 0x525 0x2125 0x9ec4 0x544 0x225f 0x9e60 0x555 0x2399 0x9df7 0x55f 0x24d3 0x9d86 0x55f 0x260e 0x9d1a 0x56b 0x2748 0x9cb1 0x57e 0x2882 0x9c53 0x59d 0x29bc 0x9bf5 0x5aa 0x2af6 0x9b96 0x5aa 0x2c31 0x9b45 0x5c9 0x2d6b 0x9af3 0x5e2 0x2ea5 0x9aa1 0x5f2 0x2fdf 0x9a36 0x5cf 0x311a 0x99c2 0x599 0x3254 0x9944 0x54a 0x338e 0x98d1 0x505 0x34c8 0x9865 0x4c7 0x3603 0x9807 0x4a7 0x373d 0x97b2 0x48f 0x3877 0x9766 0x480 0x39b1 0x9721 0x47e 0x3aec 0x96df 0x47e 0x3c26 0x96a7 0x47e 0x3d60 0x9672 0x489 0x3e9a 0x9640 0x497 0x3fd5 0x960e 0x497 0x410f 0x95d8 0x48f 0x4249 0x95a0 0x47f 0x4383 0x9579 0x48d 0x44be 0x9551 0x497 0x45f8 0x9525 0x497 0x4732 0x94fe 0x4af 0x486c 0x94d8 0x4c6 0x49a7 0x94b2 0x4b7 0x4ae1 0x948d 0x4b9 0x4c1b 0x9467 0x4c9 0x4d55 0x9447 0x4c9 0x4e90 0x942a 0x4d5 0x4fca 0x9411 0x4f5 0x5104 0x93f3 0x508 0x523e 0x93d2 0x511 0x5378 0x93ad 0x501 0x54b3 0x9383 0x4e8 0x55ed 0x9357 0x4c8 0x5727 0x9325 0x4a9 0x5861 0x92f8 0x49e 0x599c 0x92d2 0x4ad 0x5ad6 0x92a7 0x4a3 0x5c10 0x927d 0x497 0x5d4a 0x9257 0x497 0x5e85 0x9231 0x497 0x5fbf 0x920c 0x499 0x60f9 0x91ec 0x4b9 0x6233 0x91c1 0x4c2 0x636e 0x9189 0x4b2 0x64a8 0x9150 0x4b0 0x65e2 0x9117 0x4b0 0x671c 0x90df 0x4b0 0x6857 0x9095 0x4a5 0x6991 0x9048 0x497 0x6acb 0x9022 0x497 0x6c05 0x900d 0x4a7 0x6d40 0x9006 0x4c7 0x6e7a 0x8ff4 0x4e6 0x6fb4 0x8fdb 0x50b 0x70ee 0x8fb6 0x53a 0x7229 0x8efe 0x546 0x7363 0x8dea 0x54d 0x749d 0x8be7 0x57c 0x75d7 0x892e 0x5ea 0x7712 0x85eb 0x687 0x784c 0x7e7e 0xdcb 0x7986 0x7792 0x659>;
				battery3_profile_t1_num = <0x64>;
				battery3_profile_t2 = <0x0 0xaa3c 0x834 0x13a 0xa999 0x873 0x274 0xa905 0x8ab 0x3af 0xa887 0x8da 0x4e9 0xa80e 0x8e3 0x623 0xa796 0x8e7 0x75d 0xa718 0x8f6 0x898 0xa69e 0x8fc 0x9d2 0xa627 0x8fb 0xb0c 0xa5af 0x8ec 0xc46 0xa538 0x8ea 0xd81 0xa4c0 0x8fa 0xebb 0xa449 0x8fc 0xff5 0xa3d3 0x8fc 0x112f 0xa362 0x8fc 0x126a 0xa2f1 0x907 0x13a4 0xa280 0x915 0x14de 0xa20f 0x915 0x1618 0xa19e 0x91d 0x1753 0xa12d 0x92d 0x188d 0xa0c1 0x92e 0x19c7 0xa056 0x92e 0x1b01 0x9feb 0x92e 0x1c3c 0x9f8e 0x950 0x1d76 0x9f35 0x981 0x1eb0 0x9ed7 0x9c0 0x1fea 0x9e72 0x9ee 0x2125 0x9e07 0xa0d 0x225f 0x9d7f 0x9f1 0x2399 0x9cfb 0x9dd 0x24d3 0x9c84 0x9dd 0x260e 0x9c29 0xa01 0x2748 0x9bd8 0xa25 0x2882 0x9b86 0xa15 0x29bc 0x9b34 0xa18 0x2af6 0x9ae2 0xa28 0x2c31 0x9a84 0xa09 0x2d6b 0x9a1e 0x9e3 0x2ea5 0x99ad 0x9b4 0x2fdf 0x9932 0x952 0x311a 0x98ba 0x8f5 0x3254 0x9855 0x8d6 0x338e 0x97f9 0x8b6 0x34c8 0x97a1 0x898 0x3603 0x975c 0x898 0x373d 0x9717 0x891 0x3877 0x96d2 0x881 0x39b1 0x969d 0x89a 0x3aec 0x9669 0x8ad 0x3c26 0x9630 0x89d 0x3d60 0x95fc 0x8ad 0x3e9a 0x95ca 0x8cb 0x3fd5 0x959e 0x8db 0x410f 0x9572 0x8e3 0x4249 0x9546 0x8e3 0x4383 0x951a 0x8f1 0x44be 0x94f0 0x906 0x45f8 0x94cb 0x925 0x4732 0x94a9 0x939 0x486c 0x948a 0x949 0x49a7 0x946b 0x959 0x4ae1 0x944b 0x960 0x4c1b 0x942c 0x960 0x4d55 0x940c 0x97e 0x4e90 0x93ed 0x992 0x4fca 0x93cd 0x992 0x5104 0x93b2 0x992 0x523e 0x9398 0x992 0x5378 0x9378 0x992 0x54b3 0x935d 0x9a5 0x55ed 0x9343 0x9c4 0x5727 0x931d 0x9b4 0x5861 0x92f8 0x9b2 0x599c 0x92d2 0x9c1 0x5ad6 0x92b2 0x9ec 0x5c10 0x928f 0xa13 0x5d4a 0x9263 0xa23 0x5e85 0x9237 0xa47 0x5fbf 0x920a 0xa76 0x60f9 0x91d2 0xaa5 0x6233 0x9196 0xacd 0x636e 0x9157 0xaec 0x64a8 0x9118 0xb43 0x65e2 0x90d4 0xb8f 0x671c 0x9082 0xbaf 0x6857 0x905d 0xc05 0x6991 0x9049 0xc75 0x6acb 0x9030 0xcf3 0x6c05 0x901a 0xd99 0x6d40 0x9007 0xe65 0x6e7a 0x8fba 0xf6c 0x6fb4 0x8f03 0x1067 0x70ee 0x8d83 0x1143 0x7229 0x8b3f 0x12e7 0x7363 0x8861 0x151e 0x749d 0x83aa 0x190c 0x75d7 0x7bf1 0x10f9 0x7712 0x788c 0xa0f 0x784c 0x788c 0xa0f 0x7986 0x788c 0xa0f>;
				battery3_profile_t2_num = <0x64>;
				battery3_profile_t3 = <0x0 0xa942 0xc35 0x13a 0xa87f 0xe8a 0x274 0xa7d3 0x1012 0x3af 0xa749 0x1070 0x4e9 0xa6c9 0x10a8 0x623 0xa64c 0x10cc 0x75d 0xa5ce 0x10cc 0x898 0xa550 0x10d6 0x9d2 0xa4d3 0x10e6 0xb0c 0xa462 0x1106 0xc46 0xa3ee 0x1117 0xd81 0xa376 0x1117 0xebb 0xa304 0x1125 0xff5 0xa293 0x1130 0x112f 0xa222 0x1130 0x126a 0xa1b1 0x113b 0x13a4 0xa141 0x1149 0x14de 0xa0d6 0x1149 0x1618 0xa06e 0x1159 0x1753 0xa009 0x1178 0x188d 0x9fab 0x11a6 0x19c7 0x9f4e 0x11e4 0x1b01 0x9ef6 0x1242 0x1c3c 0x9e8c 0x125c 0x1d76 0x9e15 0x1254 0x1eb0 0x9d78 0x1215 0x1fea 0x9ce8 0x11ef 0x2125 0x9c64 0x11e0 0x225f 0x9bfe 0x11fd 0x2399 0x9ba1 0x1217 0x24d3 0x9b4f 0x1226 0x260e 0x9afd 0x122a 0x2748 0x9aa9 0x1224 0x2882 0x9a4b 0x1205 0x29bc 0x99e5 0x11ca 0x2af6 0x997b 0x117b 0x2c31 0x9909 0x114c 0x2d6b 0x989d 0x1117 0x2ea5 0x9839 0x10d8 0x2fdf 0x97de 0x10bf 0x311a 0x9789 0x10b3 0x3254 0x973e 0x10b3 0x338e 0x96fa 0x10bd 0x34c8 0x96bc 0x10ce 0x3603 0x9683 0x10fd 0x373d 0x964b 0x111e 0x3877 0x9612 0x112e 0x39b1 0x95df 0x1130 0x3aec 0x95ae 0x113d 0x3c26 0x9582 0x116c 0x3d60 0x9556 0x1190 0x3e9a 0x952a 0x11b0 0x3fd5 0x94fe 0x11cf 0x410f 0x94d5 0x11ee 0x4249 0x94b0 0x120e 0x4383 0x9490 0x121f 0x44be 0x946e 0x123e 0x45f8 0x9449 0x127c 0x4732 0x942c 0x12b0 0x486c 0x9414 0x12df 0x49a7 0x9401 0x130e 0x4ae1 0x93ea 0x1335 0x4c1b 0x93d1 0x1354 0x4d55 0x93be 0x1391 0x4e90 0x93ab 0x13d0 0x4fca 0x9398 0x140f 0x5104 0x9385 0x1467 0x523e 0x9370 0x14c1 0x5378 0x9350 0x1500 0x54b3 0x932d 0x153f 0x55ed 0x9307 0x157e 0x5727 0x92e1 0x15dc 0x5861 0x92bc 0x1641 0x599c 0x9296 0x16af 0x5ad6 0x9266 0x172b 0x5c10 0x9230 0x17a8 0x5d4a 0x91f2 0x1826 0x5e85 0x91b3 0x18b8 0x5fbf 0x9174 0x1958 0x60f9 0x9135 0x1a14 0x6233 0x90ed 0x1ad8 0x636e 0x909b 0x1ba4 0x64a8 0x906b 0x1c9a 0x65e2 0x9045 0x1dad 0x671c 0x902b 0x1ef7 0x6857 0x9012 0x20a4 0x6991 0x8ff5 0x228b 0x6acb 0x8fb6 0x24f0 0x6c05 0x8efb 0x276d 0x6d40 0x8dce 0x2a01 0x6e7a 0x8b8e 0x2e2d 0x6fb4 0x88ea 0x2f9d 0x70ee 0x8526 0x2830 0x7229 0x7e14 0x1686 0x7363 0x7bfc 0x11c6 0x749d 0x7bfc 0x11c6 0x75d7 0x7bfc 0x11c6 0x7712 0x7bfc 0x11c6 0x784c 0x7bfc 0x11c6 0x7986 0x7bfc 0x11c6>;
				battery3_profile_t3_num = <0x64>;
				battery3_profile_t4 = <0x0 0xa8a2 0x19c8 0x13a 0xa7a0 0x1e04 0x274 0xa68f 0x2105 0x3af 0xa568 0x2240 0x4e9 0xa498 0x2414 0x623 0xa3e7 0x25b9 0x75d 0xa35c 0x2646 0x898 0xa2da 0x2684 0x9d2 0xa25d 0x2694 0xb0c 0xa1e5 0x26a3 0xc46 0xa16e 0x26c1 0xd81 0xa0f6 0x26f1 0xebb 0xa08a 0x2720 0xff5 0xa021 0x274b 0x112f 0x9fbc 0x276a 0x126a 0x9f4f 0x277f 0x13a4 0x9edb 0x2789 0x14de 0x9e4b 0x275a 0x1618 0x9daa 0x2703 0x1753 0x9cfa 0x2686 0x188d 0x9c4a 0x2616 0x19c7 0x9ba1 0x25b7 0x1b01 0x9b08 0x2577 0x1c3c 0x9a83 0x2537 0x1d76 0x9a0b 0x2506 0x1eb0 0x99b4 0x2515 0x1fea 0x995f 0x2513 0x2125 0x990d 0x2503 0x225f 0x98c8 0x2512 0x2399 0x9883 0x251c 0x24d3 0x983e 0x251c 0x260e 0x97f9 0x251c 0x2748 0x97b4 0x251c 0x2882 0x976e 0x251c 0x29bc 0x9731 0x2539 0x2af6 0x96f8 0x2567 0x2c31 0x96b9 0x2577 0x2d6b 0x967d 0x2587 0x2ea5 0x9645 0x2597 0x2fdf 0x9612 0x25c1 0x311a 0x95df 0x25ec 0x3254 0x95ac 0x260c 0x338e 0x9579 0x2621 0x34c8 0x9548 0x2634 0x3603 0x9522 0x2663 0x373d 0x94f6 0x267a 0x3877 0x94c4 0x267a 0x39b1 0x94a3 0x26a5 0x3aec 0x9482 0x26d5 0x3c26 0x945c 0x2704 0x3d60 0x9432 0x22fb 0x3e9a 0x9407 0x1f32 0x3fd5 0x93e8 0x2575 0x410f 0x93c9 0x2870 0x4249 0x93a9 0x28cf 0x4383 0x9384 0x292d 0x44be 0x935e 0x2991 0x45f8 0x9338 0x29ff 0x4732 0x9309 0x2a61 0x486c 0x92d6 0x2ac5 0x49a7 0x92a4 0x2b43 0x4ae1 0x926e 0x2bca 0x4c1b 0x9235 0x2c57 0x4d55 0x91f7 0x2ce5 0x4e90 0x91b5 0x2d7f 0x4fca 0x9170 0x2e2c 0x5104 0x912b 0x2ed9 0x523e 0x90ea 0x2f91 0x5378 0x90b8 0x306d 0x54b3 0x9092 0x315d 0x55ed 0x9073 0x325c 0x5727 0x905a 0x3396 0x5861 0x902f 0x34d8 0x599c 0x8ff0 0x3622 0x5ad6 0x8f28 0x3735 0x5c10 0x8dfc 0x3813 0x5d4a 0x8c01 0x387e 0x5e85 0x8939 0x3217 0x5fbf 0x8557 0x2861 0x60f9 0x808e 0x1d97 0x6233 0x808e 0x1d97 0x636e 0x808e 0x1d97 0x64a8 0x808e 0x1d97 0x65e2 0x808e 0x1d97 0x671c 0x808e 0x1d97 0x6857 0x808e 0x1d97 0x6991 0x808e 0x1d97 0x6acb 0x808e 0x1d97 0x6c05 0x808e 0x1d97 0x6d40 0x808e 0x1d97 0x6e7a 0x808e 0x1d97 0x6fb4 0x808e 0x1d97 0x70ee 0x808e 0x1d97 0x7229 0x808e 0x1d97 0x7363 0x808e 0x1d97 0x749d 0x808e 0x1d97 0x75d7 0x808e 0x1d97 0x7712 0x808e 0x1d97 0x784c 0x808e 0x1d97 0x7986 0x808e 0x1d97>;
				battery3_profile_t4_num = <0x64>;
				compatible = "mediatek,bat_gm30";
				g_FG_PSEUDO100_T0 = <0x64>;
				g_FG_PSEUDO100_T1 = <0x61>;
				g_FG_PSEUDO100_T2 = <0x5f>;
				g_FG_PSEUDO100_T3 = <0x5c>;
				g_FG_PSEUDO100_T4 = <0x5a>;
				g_FG_PSEUDO1_T0 = <0x0>;
				g_FG_PSEUDO1_T1 = <0x0>;
				g_FG_PSEUDO1_T2 = <0x0>;
				g_FG_PSEUDO1_T3 = <0x0>;
				g_FG_PSEUDO1_T4 = <0x0>;
				phandle = <0x70>;
			};

			fuelgauge {
				compatible = "mediatek, fuelgauge";
				enabled = <0x1>;
				phandle = <0x80>;
			};

			kpd_volume_down {
				compatible = "mediatek, VOLUME_DOWN-eint";
				debounce = <0x7d00>;
				interrupt-parent = <0xffffffff>;
				interrupts = <0x5e 0x2 0x5e 0x0>;
				phandle = <0x7c>;
				status = "okay";
			};

			kpd_volume_up {
				compatible = "mediatek, VOLUME_UP-eint";
				debounce = <0x7d00>;
				interrupt-parent = <0xffffffff>;
				interrupts = <0x14 0x2 0x14 0x0>;
				phandle = <0x7b>;
				status = "okay";
			};

			led@0 {
				compatible = "mediatek,red";
				data = <0x1>;
				led_mode = <0x0>;
				phandle = <0x71>;
				pwm_config = <0x0 0x0 0x0 0x0 0x0>;
			};

			led@1 {
				compatible = "mediatek,green";
				data = <0x1>;
				led_mode = <0x0>;
				phandle = <0x72>;
				pwm_config = <0x0 0x0 0x0 0x0 0x0>;
			};

			led@2 {
				compatible = "mediatek,blue";
				data = <0x1>;
				led_mode = <0x0>;
				phandle = <0x73>;
				pwm_config = <0x0 0x0 0x0 0x0 0x0>;
			};

			led@3 {
				compatible = "mediatek,jogball-backlight";
				data = <0x1>;
				led_mode = <0x0>;
				phandle = <0x74>;
				pwm_config = <0x0 0x0 0x0 0x0 0x0>;
			};

			led@4 {
				compatible = "mediatek,keyboard-backlight";
				data = <0x1>;
				led_mode = <0x0>;
				phandle = <0x75>;
				pwm_config = <0x0 0x0 0x0 0x0 0x0>;
			};

			led@5 {
				compatible = "mediatek,button-backlight";
				data = <0x1>;
				led_mode = <0x0>;
				phandle = <0x76>;
				pwm_config = <0x0 0x0 0x0 0x0 0x0>;
			};

			led@6 {
				compatible = "mediatek,lcd-backlight";
				data = <0x1>;
				led_mode = <0x4>;
				phandle = <0x77>;
				pwm_config = <0x0 0x1 0x0 0x0 0x0>;
			};

			oppo_charger {
				compatible = "mediatek,oppo-charger";
				phandle = <0x7f>;
				pinctrl-0 = <0x6>;
				pinctrl-1 = <0x7>;
				pinctrl-2 = <0x8>;
				pinctrl-names = "default", "charger_gpio_as_output_low", "charger_gpio_as_output_high";
				qcom,batt_capacity_mah = <0xfb4>;
				qcom,charger_hv_thr = <0x16a8>;
				qcom,charger_lv_thr = <0xd48>;
				qcom,chargerid_switch-gpio = <0xffffffff 0x61 0x0>;
				qcom,check_batt_full_by_sw;
				qcom,chg_ctrl_by_calling;
				qcom,chg_ctrl_by_camera;
				qcom,chg_ctrl_by_lcd;
				qcom,cold_bat_decidegc = <0x14>;
				qcom,cold_vfloat_over_sw_limit = <0xf8c>;
				qcom,cold_vfloat_sw_limit = <0xf5a>;
				qcom,cool_bat_decidegc = <0x32>;
				qcom,cool_vfloat_over_sw_limit = <0x1126>;
				qcom,cool_vfloat_over_sw_limit_2nd = <0x1131>;
				qcom,cool_vfloat_sw_limit = <0x10ef>;
				qcom,default_iterm_ma = <0xc8>;
				qcom,default_iterm_ma_2nd = <0x12c>;
				qcom,default_normal_vfloat_over_sw_limit = <0x1126>;
				qcom,default_normal_vfloat_over_sw_limit_2nd = <0x1131>;
				qcom,default_normal_vfloat_sw_limit = <0x10ef>;
				qcom,default_temp_normal_fastchg_current_ma = <0x834>;
				qcom,default_temp_normal_vfloat_mv = <0x1121>;
				qcom,default_temp_normal_vfloat_mv_2nd = <0x1127>;
				qcom,ff1_normal_fastchg_ma = <0x400>;
				qcom,ffc2_exit_step_ma = <0x78>;
				qcom,ffc2_normal_fastchg_ma = <0x2d0>;
				qcom,ffc2_temp_high_decidegc = <0x190>;
				qcom,ffc2_temp_low_decidegc = <0xa0>;
				qcom,ffc2_temp_warm_decidegc = <0x15e>;
				qcom,ffc2_warm_fastchg_ma = <0x316>;
				qcom,ffc_normal_vfloat_over_sw_limit = <0x1194>;
				qcom,ffc_normal_vfloat_sw_limit = <0x114e>;
				qcom,ffc_temp_normal_vfloat_mv = <0x1194>;
				qcom,hot_bat_decidegc = <0x212>;
				qcom,input_current_calling_ma = <0x5dc>;
				qcom,input_current_camera_ma = <0x4b0>;
				qcom,input_current_cdp_ma = <0x5dc>;
				qcom,input_current_charger_ma = <0x7d0>;
				qcom,input_current_led_ma = <0x4b0>;
				qcom,input_current_led_ma_forcmcc = <0x1f4>;
				qcom,input_current_usb_ma = <0x1f4>;
				qcom,iterm_disabled = <0x0>;
				qcom,iterm_ma = <0xc8>;
				qcom,iterm_ma_2nd = <0x12c>;
				qcom,little_cold_bat_decidegc = <0x0>;
				qcom,little_cold_vfloat_over_sw_limit = <0x1126>;
				qcom,little_cold_vfloat_over_sw_limit_2nd = <0x1131>;
				qcom,little_cold_vfloat_sw_limit = <0x10ef>;
				qcom,little_cool_bat_decidegc = <0x78>;
				qcom,little_cool_vfloat_over_sw_limit = <0x1126>;
				qcom,little_cool_vfloat_over_sw_limit_2nd = <0x1131>;
				qcom,little_cool_vfloat_sw_limit = <0x10ef>;
				qcom,max_chg_time_sec = <0x8ca0>;
				qcom,non_normal_vterm_hw_inc = <0x14>;
				qcom,non_standard_fastchg_current_ma = <0x200>;
				qcom,non_standard_vfloat_mv = <0xf8c>;
				qcom,non_standard_vfloat_over_sw_limit = <0xf8c>;
				qcom,non_standard_vfloat_sw_limit = <0xf5a>;
				qcom,normal_bat_decidegc = <0xdc>;
				qcom,normal_vfloat_over_sw_limit = <0x1126>;
				qcom,normal_vfloat_over_sw_limit_2nd = <0x1131>;
				qcom,normal_vfloat_sw_limit = <0x10ef>;
				qcom,normal_vterm_hw_inc = <0x14>;
				qcom,recharge-mv = <0x73>;
				qcom,recharge-mv_2nd = <0x79>;
				qcom,removed_bat_decidegc = <0xbe>;
				qcom,short_c_bat_cv_mv = <0x10ea>;
				qcom,short_c_bat_fastchg_current_ma = <0x200>;
				qcom,short_c_bat_vfloat_mv = <0xed8>;
				qcom,short_c_bat_vfloat_sw_limit = <0xea6>;
				qcom,sw_vfloat_over_protect_enable;
				qcom,temp_cold_fastchg_current_ma = <0x168>;
				qcom,temp_cold_vfloat_mv = <0xf8c>;
				qcom,temp_cool_fastchg_current_ma_high = <0x384>;
				qcom,temp_cool_fastchg_current_ma_low = <0x20d>;
				qcom,temp_cool_vfloat_mv = <0x1121>;
				qcom,temp_cool_vfloat_mv_2nd = <0x1127>;
				qcom,temp_little_cold_fastchg_current_ma = <0x20d>;
				qcom,temp_little_cold_fastchg_current_ma_high = <0x20d>;
				qcom,temp_little_cold_fastchg_current_ma_low = <0x20d>;
				qcom,temp_little_cold_vfloat_mv = <0x1121>;
				qcom,temp_little_cold_vfloat_mv_2nd = <0x1127>;
				qcom,temp_little_cool_fastchg_current_ma = <0x668>;
				qcom,temp_little_cool_vfloat_mv = <0x1121>;
				qcom,temp_little_cool_vfloat_mv_2nd = <0x1127>;
				qcom,temp_normal_fastchg_current_ma = <0x834>;
				qcom,temp_normal_vfloat_mv = <0x1121>;
				qcom,temp_normal_vfloat_mv_2nd = <0x1127>;
				qcom,temp_warm_fastchg_current_ma = <0x44c>;
				qcom,temp_warm_vfloat_mv = <0x1022>;
				qcom,vbatt_full_thr = <0x1130>;
				qcom,vbatt_hv_thr = <0x1194>;
				qcom,vbatt_num = <0x1>;
				qcom,vbatt_power_off = <0xce4>;
				qcom,vbatt_soc_1 = <0xd52>;
				qcom,vfloat_step_mv = <0x10>;
				qcom,vooc_project = <0x0>;
				qcom,warm_bat_decidegc = <0x1c2>;
				qcom,warm_vfloat_over_sw_limit = <0x1022>;
				qcom,warm_vfloat_sw_limit = <0xff0>;
			};

			oppo_devinfo {
				Hw,sub_hwid_1 = <0xffffffff 0x3a 0x0>;
				Hw,sub_hwid_2 = <0xffffffff 0x41 0x0>;
				compatible = "oppo, device_info";
				phandle = <0x7e>;
				pinctrl-0 = <0x1>;
				pinctrl-1 = <0x2 0x3>;
				pinctrl-2 = <0x4 0x5>;
				pinctrl-names = "default", "hw_sub_id_sleep", "hw_sub_id_active";
			};

			oppo_project {
				compatible = "oppo,oppo_project";
				phandle = <0x7a>;
			};

			oppo_sensor {
				phandle = <0x7d>;
			};

			usb_c_pinctrl {
				compatible = "mediatek,usb_c_pinctrl";
				phandle = <0x79>;
			};

			vibrator@0 {
				compatible = "mediatek,vibrator";
				phandle = <0x78>;
				vib_limit = <0x0>;
				vib_timer = <0x1e>;
				vib_vol = <0xb>;
			};
		};
	};

	fragment@10 {
		target = <0xffffffff>;

		__overlay__ {

			boost_active {
				phandle = <0x25>;

				pins_cmd_dat {
					bias-disable;
					drive-strength = <0x3>;
					output-high;
					pinmux = <0xf00>;
					slew-rate = <0x1>;
				};
			};

			boost_sleep {
				phandle = <0x21>;

				pins_cmd_dat {
					bias-pull-down;
					drive-strength = <0x3>;
					output-low;
					pinmux = <0xf00>;
					slew-rate = <0x1>;
				};
			};

			dir_active {
				phandle = <0x24>;

				pins_cmd_dat {
					bias-disable;
					drive-strength = <0x0>;
					output-low;
					pinmux = <0x1000>;
					slew-rate = <0x1>;
				};
			};

			dir_sleep {
				phandle = <0x20>;

				pins_cmd_dat {
					bias-pull-up;
					drive-strength = <0x0>;
					output-high;
					pinmux = <0x1000>;
					slew-rate = <0x1>;
				};
			};

			motor_default {
				phandle = <0x1d>;
			};

			pwm_active {
				phandle = <0x23>;

				pins_cmd_dat {
					bias-disable;
					drive-strength = <0x0>;
					output-low;
					pinmux = <0x5a01>;
					slew-rate = <0x1>;
				};
			};

			pwm_sleep {
				phandle = <0x1f>;

				pins_cmd_dat {
					bias-pull-up;
					drive-strength = <0x0>;
					output-high;
					pinmux = <0x5a00>;
					slew-rate = <0x1>;
				};
			};

			sleep_active {
				phandle = <0x22>;

				pins_cmd_dat {
					bias-disable;
					drive-strength = <0x0>;
					output-low;
					pinmux = <0xe00>;
					slew-rate = <0x1>;
				};
			};

			sleep_sleep {
				phandle = <0x1e>;

				pins_cmd_dat {
					bias-pull-up;
					drive-strength = <0x0>;
					output-high;
					pinmux = <0xe00>;
					slew-rate = <0x1>;
				};
			};
		};
	};

	fragment@11 {
		target = <0xffffffff>;

		__overlay__ {
			compatible = "oppo-motor";
			delay-cycle = <0xe 0xe 0xe>;
			down-speed-param = <0x2 0x2625a>;
			full-speed-param = <0x3f 0x3c8c>;
			hall-data-sign = <0x0>;
			hall-irq-pos = <0xaa>;
			mag_noise_pattern = <0x50 0x190 0x0 0x296 0xc8 0x64 0x64>;
			mag_noise_support;
			motor-retard-pos = <0x1ae>;
			nodetect-speed-param = <0xf 0x3c8c>;
			slow-delay-cycle = <0x1c 0x1c 0x1c>;
			slow-down-speed-param = <0x2 0x2625a>;
			slow-full-speed-param = <0x3f 0x7a12>;
			slow-nodetect-speed-param = <0xf 0x196e6>;
			slow-up-speed-param = <0x5 0x196e6>;
			status = "okay";
			stop-neg-point = <0x3 0x3>;
			stop-pos-point = <0x3 0x3>;
			up-speed-param = <0x5 0x3c8c>;
		};
	};

	fragment@12 {
		target = <0xffffffff>;

		__overlay__ {
			boost-gpio = <0xffffffff 0xf 0x0>;
			compatible = "motor_drv-8834";
			dir-gpio = <0xffffffff 0x10 0x0>;
			pinctrl-0 = <0x1d>;
			pinctrl-1 = <0x1e 0x1f 0x20 0x21>;
			pinctrl-2 = <0x22 0x23 0x24 0x25>;
			pinctrl-names = "default", "motor_sleep", "motor_active";
			ratio-a = <0x18>;
			ratio-b = <0x730>;
			ratio-c = <0x14>;
			ratio-d = <0x20>;
			sleep-gpio = <0xffffffff 0xe 0x0>;
			status = "okay";
			step-gpio = <0xffffffff 0x5a 0x0>;
		};
	};

	fragment@13 {
		target = <0xffffffff>;

		__overlay__ {
			status = "okay";

			dhall0-m1120@0f {
				compatible = "oppo,dhall-m1120";
				dhall,id = <0x0>;
				dhall,irq-gpio = <0xffffffff 0x5 0x2008>;
				hall-power-gpio = <0xffffffff 0x6e 0x0>;
				interrupt-parent = <0xffffffff>;
				interrupts = <0x5 0x8 0x5 0x0>;
				pinctrl-0 = <0x26>;
				pinctrl-1 = <0x27>;
				pinctrl-2 = <0x28>;
				pinctrl-names = "hall_power_down", "hall_power_up", "hall0_interrupt_input";
				reg = <0xf>;
				status = "okay";
			};

			dhall1-m1120@0c {
				compatible = "oppo,dhall-m1120";
				dhall,id = <0x1>;
				dhall,irq-gpio = <0xffffffff 0x6 0x2008>;
				hall-power-gpio = <0xffffffff 0x6e 0x0>;
				interrupt-parent = <0xffffffff>;
				interrupts = <0x6 0x8 0x6 0x0>;
				pinctrl-0 = <0x26>;
				pinctrl-1 = <0x27>;
				pinctrl-2 = <0x29>;
				pinctrl-names = "hall_power_down", "hall_power_up", "hall1_interrupt_input";
				reg = <0xc>;
				status = "okay";
			};
		};
	};

	fragment@14 {
		target = <0xffffffff>;

		__overlay__ {

			hall0_interrupt_input {
				phandle = <0x28>;

				pins_cmd_dat {
					bias-disable;
					drive-strength = <0x2>;
					pinmux = <0x600>;
					slew-rate = <0x0>;
				};
			};

			hall1_interrupt_input {
				phandle = <0x29>;

				pins_cmd_dat {
					bias-disable;
					drive-strength = <0x2>;
					pinmux = <0x500>;
					slew-rate = <0x0>;
				};
			};

			hall_power_down {
				phandle = <0x26>;

				pins_cmd_dat {
					bias-pull-down;
					drive-strength = <0x2>;
					output-low;
					pinmux = <0x6e00>;
					slew-rate = <0x1>;
				};
			};

			hall_power_up {
				phandle = <0x27>;

				pins_cmd_dat {
					bias-pull-down;
					drive-strength = <0x2>;
					output-high;
					pinmux = <0x6e00>;
					slew-rate = <0x1>;
				};
			};
		};
	};

	fragment@15 {
		target = <0xffffffff>;

		__overlay__ {
			compatible = "mediatek,usb_iddig_bi_eint";
			pinctrl-0 = <0x2a>;
			pinctrl-1 = <0x2b>;
			pinctrl-2 = <0x2c>;
			pinctrl-names = "id_default", "id_init", "id_output_low";
			qcom,otg_switch_gpio = <0x29>;
			status = "okay";
		};
	};

	fragment@16 {
		target = <0xffffffff>;

		__overlay__ {

			id_default {
				phandle = <0x2a>;
			};

			id_init {
				phandle = <0x2b>;

				pins_cmd_dat {
					bias-pull-up = <0x65>;
					pinmux = <0x2901>;
					slew-rate = <0x0>;
				};
			};

			id_output_low {
				phandle = <0x2c>;

				pins_cmd_dat {
					output-low;
					pinmux = <0x2900>;
					slew-rate = <0x1>;
				};
			};
		};
	};

	fragment@17 {
		target = <0xffffffff>;

		__overlay__ {
			accdet-mic-mode = <0x1>;
			accdet-mic-vol = <0x7>;
			accdet-plugout-debounce = <0x1>;
			headset-eint-level-pol = <0x8>;
			headset-four-key-threshold = <0x0 0x3a 0x79 0xc0 0x190>;
			headset-mode-setting = <0x500 0x500 0x1 0x1f0 0x800 0x800 0x20 0x44>;
			headset-three-key-threshold = <0x0 0x52 0xaa 0x132>;
			headset-three-key-threshold-CDD = <0x0 0x79 0xc0 0x258>;
			status = "okay";
		};
	};

	fragment@18 {
		target = <0xffffffff>;

		__overlay__ {
			pinctrl-0 = <0x2d>;
			pinctrl-1 = <0x2e>;
			pinctrl-10 = <0x37>;
			pinctrl-11 = <0x38>;
			pinctrl-2 = <0x2f>;
			pinctrl-3 = <0x30>;
			pinctrl-4 = <0x31>;
			pinctrl-5 = <0x32>;
			pinctrl-6 = <0x33>;
			pinctrl-7 = <0x34>;
			pinctrl-8 = <0x35>;
			pinctrl-9 = <0x36>;
			pinctrl-names = "aud_dat_mosi_off", "aud_dat_mosi_on", "aud_dat_miso_off", "aud_dat_miso_on", "hpamp-pullhigh", "hpamp-pulllow", "aud_clk_mosi_off", "aud_clk_mosi_on", "audi2s0-mode0", "audi2s0-mode1", "audi2s1-mode0", "audi2s1-mode1";
			status = "okay";
		};
	};

	fragment@19 {
		target = <0xffffffff>;

		__overlay__ {

			aud_clk_mosi_off {
				phandle = <0x33>;
			};

			aud_clk_mosi_on {
				phandle = <0x34>;
			};

			aud_dat_miso_off {
				phandle = <0x2f>;
			};

			aud_dat_miso_on {
				phandle = <0x30>;
			};

			aud_dat_mosi_off {
				phandle = <0x2d>;
			};

			aud_dat_mosi_on {
				phandle = <0x2e>;
			};

			audhpamphigh {
				phandle = <0x31>;
			};

			audhpamplow {
				phandle = <0x32>;
			};

			audi2s0mode0 {
				phandle = <0x35>;

				pins_cmd_dat {
					pinmux = <0xae00>;
				};
			};

			audi2s0mode1 {
				phandle = <0x36>;

				pins_cmd_dat {
					pinmux = <0xae02>;
				};
			};

			audi2s1mode0 {
				phandle = <0x37>;

				pins_cmd0_dat {
					pinmux = <0xaa00>;
				};

				pins_cmd1_dat {
					pinmux = <0xab00>;
				};

				pins_cmd2_dat {
					pinmux = <0xac00>;
				};
			};

			audi2s1mode1 {
				phandle = <0x38>;

				pins_cmd0_dat {
					pinmux = <0xaa02>;
				};

				pins_cmd1_dat {
					pinmux = <0xab02>;
				};

				pins_cmd2_dat {
					pinmux = <0xac02>;
				};
			};
		};
	};

	fragment@2 {
		target = <0xffffffff>;

		__overlay__ {

			phy_tuning {
				compatible = "mediatek,phy_tuning";
				u2_enhance = <0x2>;
				u2_term_ref = <0x7>;
				u2_vrt_ref = <0x7>;
			};
		};
	};

	fragment@20 {
		target = <0xffffffff>;

		__overlay__ {

			consys_default {
				phandle = <0x39>;
			};

			gpslna@0 {
				phandle = <0x3a>;

				pins_cmd_dat {
					bias-disable;
					output-low;
					pinmux = <0xa900>;
					slew-rate = <0x1>;
				};
			};

			gpslna@1 {
				phandle = <0x3b>;

				pins_cmd_dat {
					output-high;
					pinmux = <0xa900>;
					slew-rate = <0x1>;
				};
			};

			gpslna@2 {
				phandle = <0x3c>;

				pins_cmd_dat {
					output-low;
					pinmux = <0xa900>;
					slew-rate = <0x1>;
				};
			};
		};
	};

	fragment@21 {
		target = <0xffffffff>;

		__overlay__ {
			pinctrl-0 = <0x39>;
			pinctrl-1 = <0x3a>;
			pinctrl-2 = <0x3b>;
			pinctrl-3 = <0x3c>;
			pinctrl-names = "default", "gps_lna_state_init", "gps_lna_state_oh", "gps_lna_state_ol";
			status = "okay";
		};
	};

	fragment@22 {
		target = <0xffffffff>;

		__overlay__ {
			pinctrl-0 = <0x3d>;
			pinctrl-1 = <0x3e>;
			pinctrl-2 = <0x3f>;
			pinctrl-3 = <0x40>;
			pinctrl-4 = <0x41>;
			pinctrl-5 = <0x42>;
			pinctrl-6 = <0x43>;
			pinctrl-names = "uart0_gpio_default", "uart0_rx_set", "uart0_rx_clear", "uart0_tx_set", "uart0_tx_clear", "uart0_rx_gpio", "uart0_tx_gpio";
			status = "okay";
		};
	};

	fragment@23 {
		target = <0xffffffff>;

		__overlay__ {

			uart0_rx_clear@gpio95 {
				phandle = <0x3f>;

				pins_cmd_dat {
					output-high;
					pinmux = <0x5f00>;
					slew-rate = <0x1>;
				};
			};

			uart0_rx_gpio@gpio95 {
				phandle = <0x42>;

				pins_cmd_dat {
					bias-disable;
					input-enable;
					pinmux = <0x5f00>;
					slew-rate = <0x0>;
				};
			};

			uart0_rx_set@gpio95 {
				phandle = <0x3e>;

				pins_cmd_dat {
					pinmux = <0x5f01>;
				};
			};

			uart0_tx_clear@gpio96 {
				phandle = <0x41>;

				pins_cmd_dat {
					output-high;
					pinmux = <0x6000>;
					slew-rate = <0x1>;
				};
			};

			uart0_tx_gpio@gpio96 {
				phandle = <0x43>;

				pins_cmd_dat {
					bias-disable;
					input-enable;
					pinmux = <0x6000>;
					slew-rate = <0x0>;
				};
			};

			uart0_tx_set@gpio96 {
				phandle = <0x40>;

				pins_cmd_dat {
					pinmux = <0x6001>;
				};
			};

			uart0gpiodefault {
				phandle = <0x3d>;
			};
		};
	};

	fragment@24 {
		target = <0xffffffff>;

		__overlay__ {

			cam0@0 {
				phandle = <0x45>;

				pins_cmd_dat {
					output-low;
					pinmux = <0x6500>;
					slew-rate = <0x1>;
				};
			};

			cam0@1 {
				phandle = <0x46>;

				pins_cmd_dat {
					output-high;
					pinmux = <0x6500>;
					slew-rate = <0x1>;
				};
			};

			cam0@vcam0 {
				phandle = <0x4b>;

				pins_cmd_dat {
					output-low;
					pinmux = <0xb300>;
					slew-rate = <0x1>;
				};
			};

			cam0@vcam1 {
				phandle = <0x4c>;

				pins_cmd_dat {
					output-high;
					pinmux = <0xb300>;
					slew-rate = <0x1>;
				};
			};

			cam1@0 {
				phandle = <0x47>;

				pins_cmd_dat {
					output-low;
					pinmux = <0x6d00>;
					slew-rate = <0x1>;
				};
			};

			cam1@1 {
				phandle = <0x48>;

				pins_cmd_dat {
					output-high;
					pinmux = <0x6d00>;
					slew-rate = <0x1>;
				};
			};

			cam1@vcamd0 {
				phandle = <0x4d>;

				pins_cmd_dat {
					output-low;
					pinmux = <0xb100>;
					slew-rate = <0x1>;
				};
			};

			cam1@vcamd1 {
				phandle = <0x4e>;

				pins_cmd_dat {
					output-high;
					pinmux = <0xb100>;
					slew-rate = <0x1>;
				};
			};

			cam2@0 {
				phandle = <0x49>;

				pins_cmd_dat {
					output-low;
					pinmux = <0x6600>;
					slew-rate = <0x1>;
				};
			};

			cam2@1 {
				phandle = <0x4a>;

				pins_cmd_dat {
					output-high;
					pinmux = <0x6600>;
					slew-rate = <0x1>;
				};
			};

			camdefault {
				phandle = <0x44>;
			};

			camera_pins_cam0_mclk_2ma {
				phandle = <0x50>;

				pins_cmd_dat {
					drive-strength = <0x0>;
					pinmux = <0x6301>;
				};
			};

			camera_pins_cam0_mclk_4ma {
				phandle = <0x51>;

				pins_cmd_dat {
					drive-strength = <0x1>;
					pinmux = <0x6301>;
				};
			};

			camera_pins_cam0_mclk_6ma {
				phandle = <0x52>;

				pins_cmd_dat {
					drive-strength = <0x2>;
					pinmux = <0x6301>;
				};
			};

			camera_pins_cam0_mclk_8ma {
				phandle = <0x53>;

				pins_cmd_dat {
					drive-strength = <0x3>;
					pinmux = <0x6301>;
				};
			};

			camera_pins_cam0_mclk_off {
				phandle = <0x4f>;

				pins_cmd_dat {
					drive-strength = <0x1>;
					pinmux = <0x6300>;
				};
			};

			camera_pins_cam1_mclk_2ma {
				phandle = <0x55>;

				pins_cmd_dat {
					drive-strength = <0x0>;
					pinmux = <0x6c01>;
				};
			};

			camera_pins_cam1_mclk_4ma {
				phandle = <0x56>;

				pins_cmd_dat {
					drive-strength = <0x1>;
					pinmux = <0x6c01>;
				};
			};

			camera_pins_cam1_mclk_6ma {
				phandle = <0x57>;

				pins_cmd_dat {
					drive-strength = <0x2>;
					pinmux = <0x6c01>;
				};
			};

			camera_pins_cam1_mclk_8ma {
				phandle = <0x58>;

				pins_cmd_dat {
					drive-strength = <0x3>;
					pinmux = <0x6c01>;
				};
			};

			camera_pins_cam1_mclk_off {
				phandle = <0x54>;

				pins_cmd_dat {
					drive-strength = <0x1>;
					pinmux = <0x6c00>;
				};
			};

			camera_pins_cam2_mclk_2ma {
				phandle = <0x5a>;

				pins_cmd_dat {
					drive-strength = <0x0>;
					pinmux = <0x6401>;
				};
			};

			camera_pins_cam2_mclk_4ma {
				phandle = <0x5b>;

				pins_cmd_dat {
					drive-strength = <0x1>;
					pinmux = <0x6401>;
				};
			};

			camera_pins_cam2_mclk_6ma {
				phandle = <0x5c>;

				pins_cmd_dat {
					drive-strength = <0x2>;
					pinmux = <0x6401>;
				};
			};

			camera_pins_cam2_mclk_8ma {
				phandle = <0x5d>;

				pins_cmd_dat {
					drive-strength = <0x3>;
					pinmux = <0x6401>;
				};
			};

			camera_pins_cam2_mclk_off {
				phandle = <0x59>;

				pins_cmd_dat {
					drive-strength = <0x1>;
					pinmux = <0x6400>;
				};
			};
		};
	};

	fragment@25 {
		target = <0xffffffff>;

		__overlay__ {
			cam0_enable_sensor = "s5kgm1sp_mipi_raw imx398_mipi_raw";
			cam0_vcama-supply = <0xffffffff>;
			cam0_vcamio-supply = <0xffffffff>;
			cam1_enable_sensor = "s5k3p9sp_mipi_raw";
			cam1_vcama-supply = <0xffffffff>;
			cam1_vcamio-supply = <0xffffffff>;
			cam2_enable_sensor = "gc5035_mipi_raw gc2375h_mipi_raw";
			cam2_vcama-supply = <0xffffffff>;
			cam2_vcamd-supply = <0xffffffff>;
			cam2_vcamio-supply = <0xffffffff>;
			pinctrl-0 = <0x44>;
			pinctrl-1 = <0x45>;
			pinctrl-10 = <0x4e>;
			pinctrl-11 = <0x4f>;
			pinctrl-12 = <0x50>;
			pinctrl-13 = <0x51>;
			pinctrl-14 = <0x52>;
			pinctrl-15 = <0x53>;
			pinctrl-16 = <0x54>;
			pinctrl-17 = <0x55>;
			pinctrl-18 = <0x56>;
			pinctrl-19 = <0x57>;
			pinctrl-2 = <0x46>;
			pinctrl-20 = <0x58>;
			pinctrl-21 = <0x59>;
			pinctrl-22 = <0x5a>;
			pinctrl-23 = <0x5b>;
			pinctrl-24 = <0x5c>;
			pinctrl-25 = <0x5d>;
			pinctrl-3 = <0x47>;
			pinctrl-4 = <0x48>;
			pinctrl-5 = <0x49>;
			pinctrl-6 = <0x4a>;
			pinctrl-7 = <0x4b>;
			pinctrl-8 = <0x4c>;
			pinctrl-9 = <0x4d>;
			pinctrl-names = "default", "cam0_rst0", "cam0_rst1", "cam1_rst0", "cam1_rst1", "cam2_rst0", "cam2_rst1", "cam0_ldo_vcamd_0", "cam0_ldo_vcamd_1", "cam1_ldo_vcamd_0", "cam1_ldo_vcamd_1", "cam0_mclk_off", "cam0_mclk_2mA", "cam0_mclk_4mA", "cam0_mclk_6mA", "cam0_mclk_8mA", "cam1_mclk_off", "cam1_mclk_2mA", "cam1_mclk_4mA", "cam1_mclk_6mA", "cam1_mclk_8mA", "cam2_mclk_off", "cam2_mclk_2mA", "cam2_mclk_4mA", "cam2_mclk_6mA", "cam2_mclk_8mA";
			status = "okay";
		};
	};

	fragment@26 {
		target = <0xffffffff>;

		__overlay__ {
			pinctrl-0 = <0x5e>;
			pinctrl-1 = <0x5f>;
			pinctrl-names = "irtx_gpio_led_default", "irtx_gpio_led_set";
			status = "okay";
		};
	};

	fragment@27 {
		target = <0xffffffff>;

		__overlay__ {

			irtx_gpio_led_def@gpio90 {
				phandle = <0x5e>;

				pins_cmd_dat {
					bias-disable;
					input-schmitt-enable = <0x0>;
					output-low;
					pinmux = <0x5a00>;
					slew-rate = <0x1>;
				};
			};

			irtx_gpio_led_set@gpio90 {
				phandle = <0x5f>;

				pins_cmd_dat {
					output-high;
					pinmux = <0x5a01>;
					slew-rate = <0x1>;
				};
			};
		};
	};

	fragment@28 {
		target = <0xffffffff>;

		__overlay__ {
			mt6370,intr_gpio = <0xffffffff 0xa 0x0>;
			mt6370,intr_gpio_num = <0xa>;
		};
	};

	fragment@29 {
		target = <0xffffffff>;

		__overlay__ {
			mt6370pd,intr_gpio = <0xffffffff 0x29 0x0>;
			mt6370pd,intr_gpio_num = <0x29>;
		};
	};

	fragment@3 {
		target = <0xffffffff>;

		__overlay__ {
			core_1 = "enable";
			scp_sramSize = <0x80000>;
		};
	};

	fragment@30 {
		target = <0xffffffff>;

		__overlay__ {
			keypad,volume-down = <0xffffffff 0x5e 0x0>;
			keypad,volume-up = <0xffffffff 0x14 0x0>;
			pinctrl-0 = <0x60>;
			pinctrl-1 = <0x61>;
			pinctrl-names = "volume_up_as_int", "volume_down_as_int";
			status = "okay";
		};
	};

	fragment@31 {
		target = <0xffffffff>;

		__overlay__ {

			volume_down@0 {
				phandle = <0x61>;

				pins_cmd_dat {
					bias-pull-up = <0x0>;
					input-enable;
					pinmux = <0x5e00>;
					slew-rate = <0x0>;
				};
			};

			volume_up@0 {
				phandle = <0x60>;

				pins_cmd_dat {
					bias-pull-up = <0x0>;
					input-enable;
					pinmux = <0x1400>;
					slew-rate = <0x0>;
				};
			};
		};
	};

	fragment@32 {
		target = <0xffffffff>;

		__overlay__ {
			pinctrl-0 = <0x62>;
			pinctrl-1 = <0x63>;
			pinctrl-names = "msdc1_on", "msdc1_off";
			status = "okay";
		};
	};

	fragment@33 {
		target = <0xffffffff>;

		__overlay__ {

			sd0@0 {
				phandle = <0x62>;

				pins_cmd_dat {
					output-high;
					pinmux = <0x5a00>;
					slew-rate = <0x1>;
				};
			};

			sd0@1 {
				phandle = <0x63>;

				pins_cmd_dat {
					output-low;
					pinmux = <0x5a00>;
					slew-rate = <0x1>;
				};
			};
		};
	};

	fragment@34 {
		target = <0xffffffff>;

		__overlay__ {
			algorithm_name = "DualSwitchCharging";
			chg1_ta_ac_charger_current = <0x1e8480>;
			chg2_ta_ac_charger_current = <0x1e8480>;
		};
	};

	fragment@35 {
		target = <0xffffffff>;

		__overlay__ {

			charger_gpio_as_output_high {
				phandle = <0x8>;

				pins_cmd_dat {
					output-high;
					pinmux = <0x6100>;
					slew-rate = <0x1>;
				};
			};

			charger_gpio_as_output_low {
				phandle = <0x7>;

				pins_cmd_dat {
					output-low;
					pinmux = <0x6100>;
					slew-rate = <0x1>;
				};
			};

			eint0default {
				phandle = <0x6>;
			};
		};
	};

	fragment@36 {
		target = <0xffffffff>;

		__overlay__ {
		};
	};

	fragment@37 {
		target = <0xffffffff>;

		__overlay__ {
			#address-cells = <0x1>;
			#size-cells = <0x0>;
			status = "ok";

			touchscreen@0 {
				black_gesture_support;
				black_gesture_test_support;
				charger_pump_support;
				chip-name = "OPPO_TP_NOFLASH";
				compatible = "oppo,tp_noflash";
				freq_hop_simulate_support;
				fw_edge_limit_support;
				fw_update_app_support;
				game_switch_support;
				headset_pump_support;
				incell_screen;
				interrupt-parent = <0xffffffff>;
				interrupts = <0x1 0x1 0x1 0x0>;
				irq-gpio = <0xffffffff 0x1 0x2001>;
				lcd-reset-gpio = <0xffffffff 0x2d 0x0>;
				lcd_trigger_load_tp_fw_support;
				noflash_support;
				pressure_report_support;
				reg = <0x0>;
				reset-gpio = <0xffffffff 0x2a 0x0>;
				smart_gesture_support;
				spi-max-frequency = <0x927c00>;
				status = "okay";
				synaptics,block-delay-us = <0x0>;
				synaptics,byte-delay-us = <0x0>;
				synaptics,grip-darkzone-area = <0xf4 0x45>;
				synaptics,irq-on-state = <0x0>;
				synaptics,irq_trigger_hdl_support;
				synaptics,power-delay-ms = <0xc8>;
				synaptics,reset-active-ms = <0x14>;
				synaptics,reset-delay-ms = <0xc8>;
				synaptics,reset-on-state = <0x0>;
				synaptics,spi-mode = <0x3>;
				synaptics,ubl-byte-delay-us = <0x14>;
				synaptics,ubl-max-freq = <0xf4240>;
				touchpanel,button-type = <0x4>;
				touchpanel,display-coords = <0x438 0x924>;
				touchpanel,max-num-support = <0xa>;
				touchpanel,panel-coords = <0x438 0x924>;
				touchpanel,tx-rx-num = <0x10 0x24>;
			};
		};
	};

	fragment@38 {
		target = <0xffffffff>;

		__overlay__ {

			goodix_irq_no_pull {
				phandle = <0x67>;

				pins_cmd_dat {
					bias-disable;
					pinmux = <0xa00>;
					slew-rate = <0x0>;
				};
			};

			goodix_irq_out_low {
				phandle = <0x66>;

				pins_cmd_dat {
					bias-pull-up = <0x0>;
					input-enable;
					pinmux = <0xa00>;
					slew-rate = <0x0>;
				};
			};

			goodix_ldo_default {
				phandle = <0x65>;

				pins_cmd_dat {
					bias-disable;
					output-low;
					pinmux = <0xb000>;
					slew-rate = <0x1>;
				};
			};

			goodix_reset_default {
				phandle = <0x64>;

				pins_cmd_dat {
					output-low;
					pinmux = <0x4f00>;
					slew-rate = <0x1>;
				};
			};

			gpio_goodix_cs_func {
				phandle = <0x68>;

				pins_cmd_dat {
					drive-strength = <0x3>;
					pinmux = <0x5601>;
				};
			};
		};
	};

	fragment@39 {
		target = <0xffffffff>;

		__overlay__ {
			goodix,gpio_cs = <0xffffffff 0x56 0x0>;
			goodix,gpio_irq = <0xffffffff 0xa 0x0>;
			goodix,gpio_ldo = <0xffffffff 0xb0 0x0>;
			goodix,gpio_reset = <0xffffffff 0x4f 0x0>;
			interrupt-parent = <0xffffffff>;
			interrupts = <0xa 0x0>;
			pinctrl-0 = <0x64>;
			pinctrl-1 = <0x65>;
			pinctrl-2 = <0x66>;
			pinctrl-3 = <0x67>;
			pinctrl-4 = <0x68>;
			pinctrl-names = "goodix_reset_default", "goodix_ldo_default", "goodix_irq_out_low", "goodix_irq_no_pull", "gf_cs_func";
			spi-max-frequency = <0x7a1200>;
			status = "okay";
		};
	};

	fragment@4 {
		target = <0xffffffff>;

		__overlay__ {
			#address-cells = <0x1>;
			#size-cells = <0x0>;

			i2c_bl_lm3697@36 {
				compatible = "mediatek,i2c_bl_lm3697";
				reg = <0x36>;
				status = "okay";
			};

			i2c_lcd_bias@3e {
				compatible = "mediatek,i2c_lcd_bias";
				reg = <0x3e>;
				status = "okay";
			};
		};
	};

	fragment@40 {
		target = <0xffffffff>;

		__overlay__ {

			fpc_irq_default {
				phandle = <0x6a>;

				pins_cmd_dat {
					bias-pull-up = <0x0>;
					pinmux = <0xa00>;
					slew-rate = <0x0>;
				};
			};

			fpc_pwr_default {
				phandle = <0x6b>;

				pins_cmd_dat {
					bias-disable;
					output-low;
					pinmux = <0xb000>;
					slew-rate = <0x1>;
				};
			};

			fpc_reset_default {
				phandle = <0x69>;

				pins_cmd_dat {
					output-low;
					pinmux = <0x4f00>;
					slew-rate = <0x1>;
				};
			};

			gpio_fpc_cs_func {
				phandle = <0x6c>;

				pins_cmd_dat {
					drive-strength = <0x3>;
					pinmux = <0x5601>;
				};
			};
		};
	};

	fragment@41 {
		target = <0xffffffff>;

		__overlay__ {
			fpc,gpio_cs = <0xffffffff 0x56 0x0>;
			fpc,irq-gpio = <0xffffffff 0xa 0x0>;
			fpc,reset-gpio = <0xffffffff 0x4f 0x0>;
			fpc,vdd-en = <0xffffffff 0xb0 0x0>;
			pinctrl-0 = <0x69 0x6a 0x6b>;
			pinctrl-1 = <0x6c>;
			pinctrl-names = "default", "fpc_cs_func";
			status = "okay";

			power_source_1 {
				delay-time = <0x0>;
				power-mode = <0x2>;
				power-name = "fpc,vdd-en";
				poweron-level = <0x1>;
			};
		};
	};

	fragment@42 {
		target = <0xffffffff>;

		__overlay__ {
			#address-cells = <0x1>;
			#size-cells = <0x0>;
			status = "okay";

			fingerprint@0 {
				compatible = "oppo,oppo_fp";
				ldo_gpio = <0xffffffff 0xb0 0x0>;
				phandle = <0x81>;
				reg = <0x0>;
				spi-id = <0x0>;
				spi-irq = <0x27>;
				spi-max-frequency = <0x7a1200>;
				spi-reg = <0xa7ffd0>;
				status = "okay";

				power_source_1 {
					delay-time = <0x0>;
					power-mode = <0x2>;
					power-name = "ldo_gpio";
					poweron-level = <0x1>;
				};
			};
		};
	};

	fragment@43 {
		target = <0xffffffff>;

		__overlay__ {

			gpio_id0_default {
				phandle = <0x6d>;

				pins_cmd_dat {
					bias-pull-up = <0x0>;
					input-enable;
					pinmux = <0xd00>;
					slew-rate = <0x0>;
				};
			};
		};
	};

	fragment@44 {
		target = <0xffffffff>;

		__overlay__ {
			oppo,fp-id0 = <0xffffffff 0xd 0x0>;
			oppo,fp_gpio = <0x14d>;
			pinctrl-0 = <0x6d>;
			pinctrl-names = "default";

			fpc_id {
				chip-name = "F_1511";
				eng-menu = "-1,-1";
				oppo,fp-id = <0x1>;
				vendor-chip = <0x6>;
			};

			goodix_id {
				chip-name = "G_5658";
				eng-menu = "-1,-1";
				oppo,fp-id = <0x0>;
				vendor-chip = <0x5>;
			};
		};
	};

	fragment@45 {
		target = <0xffffffff>;

		__overlay__ {

			adc_channel@ {
				compatible = "mediatek,adc_channel";
				mediatek,adc_fdd_rf_params_dynamic_custom_ch = <0x2>;
				mediatek,temperature0 = <0x0>;
				mediatek,temperature1 = <0x1>;
				status = "okay";
			};
		};
	};

	fragment@46 {
		target = <0xffffffff>;

		__overlay__ {
			mediatek,clkbuf-config = <0x2 0x1 0x1 0x2 0x0 0x0 0x1>;
			mediatek,clkbuf-driving-current = <0xffffffff 0xffffffff 0xffffffff 0xffffffff 0xffffffff 0xffffffff 0xffffffff>;
			mediatek,clkbuf-quantity = <0x7>;
			status = "okay";
		};
	};

	fragment@47 {
		target = <0xffffffff>;

		__overlay__ {
			#address-cells = <0x1>;
			#size-cells = <0x0>;
			clock-frequency = <0x61a80>;
			mediatek,use-open-drain;

			cap_touch@5d {
				compatible = "mediatek,cap_touch";
				phandle = <0x82>;
				reg = <0x5d>;
				status = "okay";
			};
		};
	};

	fragment@48 {
		target = <0xffffffff>;

		__overlay__ {
			#address-cells = <0x1>;
			#size-cells = <0x0>;
			clock-frequency = <0x61a80>;
			mediatek,use-open-drain;

			alsps@51 {
				compatible = "mediatek,alsps";
				interrupt-parent = <0xffffffff>;
				interrupts = <0x6 0x8 0x6 0x0>;
				phandle = <0x84>;
				reg = <0x51>;
				status = "okay";
			};

			barometer@77 {
				compatible = "mediatek,barometer";
				phandle = <0x85>;
				reg = <0x77>;
				status = "okay";
			};

			msensor@0c {
				compatible = "mediatek,msensor";
				phandle = <0x83>;
				reg = <0xc>;
				status = "okay";
			};
		};
	};

	fragment@49 {
		target = <0xffffffff>;

		__overlay__ {
			#address-cells = <0x1>;
			#size-cells = <0x0>;
			clock-frequency = <0x61a80>;
			mediatek,use-open-drain;

			camera_main_two@10 {
				compatible = "mediatek,camera_main_two";
				phandle = <0x86>;
				reg = <0x10>;
				status = "okay";
			};

			camera_main_two_eeprom@51 {
				compatible = "mediatek,camera_main_two_eeprom";
				phandle = <0x87>;
				reg = <0x51>;
				status = "okay";
			};

			ccu_sensor_i2c_2_hw@36 {
				compatible = "mediatek,ccu_sensor_i2c_2_hw";
				phandle = <0x88>;
				reg = <0x36>;
				status = "okay";
			};
		};
	};

	fragment@5 {
		target = <0xffffffff>;

		__overlay__ {

			default {
				phandle = <0x9>;
			};

			lcd_1p8_en0_gpio {
				phandle = <0x14>;

				pins_cmd_dat {
					output-low;
					pinmux = <0x2e00>;
					slew-rate = <0x1>;
				};
			};

			lcd_1p8_en1_gpio {
				phandle = <0x15>;

				pins_cmd_dat {
					output-high;
					pinmux = <0x2e00>;
					slew-rate = <0x1>;
				};
			};

			lcd_bias_enn0_gpio {
				phandle = <0x10>;

				pins_cmd_dat {
					output-low;
					pinmux = <0xb200>;
					slew-rate = <0x1>;
				};
			};

			lcd_bias_enn1_gpio {
				phandle = <0x11>;

				pins_cmd_dat {
					output-high;
					pinmux = <0xb200>;
					slew-rate = <0x1>;
				};
			};

			lcd_bias_enp0_gpio {
				phandle = <0xe>;

				pins_cmd_dat {
					output-low;
					pinmux = <0x9f00>;
					slew-rate = <0x1>;
				};
			};

			lcd_bias_enp1_gpio {
				phandle = <0xf>;

				pins_cmd_dat {
					output-high;
					pinmux = <0x9f00>;
					slew-rate = <0x1>;
				};
			};

			lcd_bl_en0_gpio {
				phandle = <0x12>;

				pins_cmd_dat {
					output-low;
					pinmux = <0xaf00>;
					slew-rate = <0x1>;
				};
			};

			lcd_bl_en1_gpio {
				phandle = <0x13>;

				pins_cmd_dat {
					output-high;
					pinmux = <0xaf00>;
					slew-rate = <0x1>;
				};
			};

			lcm_rst_out0_gpio {
				phandle = <0xc>;

				pins_cmd_dat {
					output-low;
					pinmux = <0x2d00>;
					slew-rate = <0x1>;
				};
			};

			lcm_rst_out1_gpio {
				phandle = <0xd>;

				pins_cmd_dat {
					output-high;
					pinmux = <0x2d00>;
					slew-rate = <0x1>;
				};
			};

			mode_te_gpio {
				phandle = <0xa>;

				pins_cmd_dat {
					pinmux = <0x2c00>;
				};
			};

			mode_te_te {
				phandle = <0xb>;

				pins_cmd_dat {
					pinmux = <0x2c01>;
				};
			};

			spi_clk_en0_gpio {
				phandle = <0x17>;

				pins_cmd_dat {
					output-low;
					pinmux = <0x1800>;
					slew-rate = <0x1>;
				};
			};

			spi_clk_en1_gpio {
				phandle = <0x19>;

				pins_cmd_dat {
					drive-strength = <0x0>;
					pinmux = <0x1802>;
				};
			};

			spi_csn_en0_gpio {
				phandle = <0x16>;

				pins_cmd_dat {
					output-low;
					pinmux = <0x1600>;
					slew-rate = <0x1>;
				};
			};

			spi_csn_en1_gpio {
				phandle = <0x18>;

				pins_cmd_dat {
					drive-strength = <0x0>;
					output-high;
					pinmux = <0x1602>;
				};
			};
		};
	};

	fragment@50 {
		target = <0xffffffff>;

		__overlay__ {
			#address-cells = <0x1>;
			#size-cells = <0x0>;
			clock-frequency = <0x61a80>;
			mediatek,use-open-drain;

			nfc@08 {
				compatible = "mediatek,nfc";
				phandle = <0x89>;
				reg = <0x8>;
				status = "okay";
			};
		};
	};

	fragment@51 {
		target = <0xffffffff>;

		__overlay__ {
			#address-cells = <0x1>;
			#size-cells = <0x0>;
			clock-frequency = <0x61a80>;
			mediatek,use-open-drain;

			camera_main@1a {
				compatible = "mediatek,camera_main";
				phandle = <0x8a>;
				reg = <0x1a>;
				status = "okay";
			};

			camera_main_af@72 {
				compatible = "mediatek,camera_main_af";
				phandle = <0x8b>;
				reg = <0x72>;
				status = "okay";
			};

			camera_main_eeprom@50 {
				compatible = "mediatek,camera_main_eeprom";
				phandle = <0x8c>;
				reg = <0x50>;
				status = "okay";
			};

			camera_main_two_af@72 {
				compatible = "mediatek,camera_main_two_af";
				phandle = <0x8d>;
				reg = <0x72>;
				status = "okay";
			};

			camera_sub@35 {
				compatible = "mediatek,camera_sub";
				phandle = <0x8e>;
				reg = <0x35>;
				status = "okay";
			};

			camera_sub_eeprom@54 {
				compatible = "mediatek,camera_sub_eeprom";
				phandle = <0x8f>;
				reg = <0x54>;
				status = "okay";
			};

			ccu_sensor_i2c_4_hw@33 {
				compatible = "mediatek,ccu_sensor_i2c_4_hw";
				phandle = <0x90>;
				reg = <0x33>;
				status = "okay";
			};

			strobe_main@63 {
				compatible = "mediatek,strobe_main";
				phandle = <0x91>;
				reg = <0x63>;
				status = "okay";
			};

			strobe_main_2@64 {
				compatible = "mediatek,strobe_main_2";
				phandle = <0x92>;
				reg = <0x64>;
				status = "okay";
			};
		};
	};

	fragment@52 {
		target = <0xffffffff>;

		__overlay__ {
			#address-cells = <0x1>;
			#size-cells = <0x0>;
			clock-frequency = <0x61a80>;
			mediatek,use-open-drain;

			subpmic_pmu@37 {
				compatible = "mediatek,subpmic_pmu";
				phandle = <0x94>;
				reg = <0x37>;
				status = "okay";
			};

			usb_type_c@4e {
				compatible = "mediatek,usb_type_c";
				phandle = <0x93>;
				reg = <0x4e>;
				status = "okay";
			};
		};
	};

	fragment@53 {
		target = <0xffffffff>;

		__overlay__ {
			#address-cells = <0x1>;
			#size-cells = <0x0>;
			clock-frequency = <0x61a80>;
			mediatek,use-open-drain;

			slave_charger@4b {
				compatible = "mediatek,slave_charger";
				phandle = <0x96>;
				reg = <0x4b>;
				status = "okay";
			};

			speaker_amp@34 {
				compatible = "mediatek,speaker_amp";
				phandle = <0x95>;
				reg = <0x34>;
				status = "okay";
			};
		};
	};

	fragment@54 {
		target = <0xffffffff>;

		__overlay__ {
			#address-cells = <0x1>;
			#size-cells = <0x0>;
			clock-frequency = <0x61a80>;
			mediatek,use-open-drain;
		};
	};

	fragment@55 {
		target = <0xffffffff>;

		__overlay__ {
			#address-cells = <0x1>;
			#size-cells = <0x0>;
			clock-frequency = <0x61a80>;
			mediatek,use-open-drain;
		};
	};

	fragment@56 {
		target = <0xffffffff>;

		__overlay__ {
			#address-cells = <0x1>;
			#size-cells = <0x0>;
			clock-frequency = <0x61a80>;
			mediatek,use-open-drain;
		};
	};

	fragment@57 {
		target = <0xffffffff>;

		__overlay__ {
			#address-cells = <0x1>;
			#size-cells = <0x0>;
			clock-frequency = <0x61a80>;
			mediatek,use-open-drain;
		};
	};

	fragment@58 {
		target = <0xffffffff>;

		__overlay__ {
			#address-cells = <0x1>;
			#size-cells = <0x0>;
			clock-frequency = <0x61a80>;
			mediatek,use-open-drain;
		};
	};

	fragment@59 {
		target = <0xffffffff>;

		__overlay__ {
			GPIO_SIM1_HOT_PLUG = <0xffffffff 0x2f 0x0>;
			GPIO_SIM1_SCLK = <0xffffffff 0x26 0x0>;
			GPIO_SIM1_SIO = <0xffffffff 0x28 0x0>;
			GPIO_SIM1_SRST = <0xffffffff 0x27 0x0>;
			GPIO_SIM2_SCLK = <0xffffffff 0x25 0x0>;
			GPIO_SIM2_SIO = <0xffffffff 0x23 0x0>;
			GPIO_SIM2_SRST = <0xffffffff 0x24 0x0>;
		};
	};

	fragment@6 {
		target = <0xffffffff>;

		__overlay__ {
			oppo_display_bl_set_cmdq_on_lcd_esd_recovery = <0x1>;
			oppo_display_cabc_cmdq_support;
			oppo_display_dyn_data_rate = <0x464>;
			oppo_display_dyn_dsi_hbp = <0x94>;
			oppo_display_elevenbits_support;
			oppo_display_esd_try_count = <0x9>;
			oppo_display_ffl_support;
			oppo_display_mipi_before_init = <0x1>;
			oppo_display_sau_support;
			pinctrl-0 = <0x9>;
			pinctrl-1 = <0xa>;
			pinctrl-10 = <0x13>;
			pinctrl-11 = <0x14>;
			pinctrl-12 = <0x15>;
			pinctrl-13 = <0x16 0x17>;
			pinctrl-14 = <0x18 0x19>;
			pinctrl-2 = <0xb>;
			pinctrl-3 = <0xc>;
			pinctrl-4 = <0xd>;
			pinctrl-5 = <0xe>;
			pinctrl-6 = <0xf>;
			pinctrl-7 = <0x10>;
			pinctrl-8 = <0x11>;
			pinctrl-9 = <0x12>;
			pinctrl-names = "default", "mode_te_gpio", "mode_te_te", "lcm_rst_out0_gpio", "lcm_rst_out1_gpio", "lcd_bias_enp0_gpio", "lcd_bias_enp1_gpio", "lcd_bias_enn0_gpio", "lcd_bias_enn1_gpio", "lcd_bl_en0_gpio", "lcd_bl_en1_gpio", "lcd_1p8_en0_gpio", "lcd_1p8_en1_gpio", "spi_csn_en0_gpio", "spi_csn_en1_gpio";
			status = "okay";
		};
	};

	fragment@60 {
		target = <0xffffffff>;

		__overlay__ {
			gpio_init_default = <0x0 0x0 0x0 0x0 0x1 0x1 0x1 0x1 0x0 0x0 0x0 0x0 0x0 0x1 0x2 0x0 0x0 0x0 0x1 0x1 0x1 0x3 0x0 0x0 0x0 0x1 0x1 0x1 0x4 0x0 0x0 0x0 0x1 0x0 0x0 0x5 0x0 0x0 0x0 0x1 0x1 0x0 0x6 0x0 0x0 0x0 0x1 0x1 0x0 0x7 0x0 0x0 0x0 0x1 0x1 0x0 0x8 0x7 0x0 0x0 0x1 0x1 0x0 0x9 0x0 0x0 0x0 0x1 0x1 0x0 0xa 0x0 0x0 0x0 0x1 0x0 0x0 0xb 0x3 0x0 0x0 0x0 0x0 0x0 0xc 0x3 0x0 0x0 0x0 0x0 0x0 0xd 0x0 0x0 0x0 0x1 0x1 0x0 0xe 0x0 0x0 0x0 0x0 0x0 0x0 0xf 0x0 0x1 0x0 0x1 0x0 0x0 0x10 0x0 0x1 0x0 0x1 0x0 0x0 0x11 0x0 0x0 0x0 0x1 0x0 0x0 0x12 0x0 0x1 0x1 0x1 0x0 0x0 0x13 0x0 0x1 0x1 0x0 0x0 0x0 0x14 0x0 0x0 0x0 0x1 0x0 0x0 0x15 0x2 0x0 0x0 0x1 0x0 0x0 0x16 0x0 0x1 0x0 0x0 0x0 0x0 0x17 0x2 0x1 0x0 0x0 0x0 0x0 0x18 0x2 0x1 0x0 0x0 0x0 0x0 0x19 0x0 0x0 0x0 0x1 0x0 0x0 0x1a 0x0 0x0 0x0 0x1 0x0 0x0 0x1b 0x5 0x1 0x0 0x0 0x0 0x0 0x1c 0x5 0x0 0x0 0x1 0x1 0x0 0x1d 0x1 0x1 0x0 0x0 0x0 0x0 0x1e 0x1 0x0 0x0 0x1 0x1 0x0 0x1f 0x1 0x0 0x0 0x1 0x1 0x0 0x20 0x1 0x0 0x0 0x1 0x1 0x0 0x21 0x1 0x0 0x0 0x1 0x1 0x0 0x22 0x1 0x0 0x0 0x1 0x1 0x0 0x23 0x1 0x0 0x0 0x1 0x1 0x0 0x24 0x1 0x1 0x0 0x0 0x0 0x0 0x25 0x1 0x1 0x0 0x0 0x0 0x0 0x26 0x1 0x1 0x0 0x0 0x0 0x0 0x27 0x1 0x1 0x0 0x0 0x0 0x0 0x28 0x1 0x0 0x0 0x1 0x1 0x0 0x29 0x0 0x0 0x0 0x1 0x1 0x0 0x2a 0x0 0x1 0x0 0x0 0x0 0x0 0x2b 0x0 0x0 0x0 0x1 0x0 0x0 0x2c 0x1 0x0 0x0 0x1 0x0 0x0 0x2d 0x0 0x1 0x0 0x0 0x0 0x0 0x2e 0x0 0x1 0x0 0x0 0x0 0x0 0x2f 0x1 0x0 0x0 0x1 0x1 0x0 0x30 0x1 0x0 0x0 0x0 0x0 0x0 0x31 0x1 0x0 0x0 0x0 0x0 0x0 0x32 0x1 0x0 0x0 0x1 0x1 0x0 0x33 0x1 0x0 0x0 0x1 0x1 0x0 0x34 0x1 0x1 0x0 0x1 0x0 0x0 0x35 0x1 0x1 0x0 0x1 0x0 0x0 0x36 0x1 0x1 0x0 0x1 0x0 0x0 0x37 0x0 0x0 0x0 0x0 0x0 0x0 0x38 0x1 0x1 0x0 0x1 0x0 0x0 0x39 0x1 0x1 0x0 0x1 0x0 0x0 0x3a 0x0 0x0 0x0 0x1 0x1 0x0 0x3b 0x1 0x0 0x0 0x1 0x0 0x0 0x3c 0x1 0x0 0x0 0x1 0x0 0x0 0x3d 0x1 0x0 0x0 0x1 0x0 0x0 0x3e 0x1 0x0 0x0 0x1 0x0 0x0 0x3f 0x1 0x0 0x0 0x1 0x0 0x0 0x40 0x1 0x0 0x0 0x1 0x0 0x0 0x41 0x0 0x0 0x0 0x1 0x1 0x0 0x42 0x2 0x0 0x0 0x1 0x0 0x0 0x43 0x1 0x0 0x0 0x1 0x0 0x0 0x44 0x1 0x0 0x0 0x1 0x0 0x0 0x45 0x1 0x1 0x0 0x1 0x0 0x0 0x46 0x1 0x1 0x0 0x1 0x0 0x0 0x47 0x1 0x1 0x0 0x1 0x0 0x0 0x48 0x1 0x1 0x0 0x1 0x0 0x0 0x49 0x1 0x1 0x0 0x1 0x0 0x0 0x4a 0x1 0x1 0x0 0x1 0x0 0x0 0x4b 0x1 0x1 0x0 0x1 0x0 0x0 0x4c 0x1 0x1 0x0 0x1 0x0 0x0 0x4d 0x0 0x0 0x0 0x1 0x0 0x0 0x4e 0x1 0x1 0x0 0x1 0x0 0x0 0x4f 0x1 0x1 0x0 0x1 0x0 0x0 0x50 0x1 0x0 0x0 0x1 0x0 0x0 0x51 0x1 0x0 0x0 0x1 0x1 0x0 0x52 0x1 0x0 0x0 0x1 0x1 0x0 0x53 0x1 0x0 0x0 0x1 0x1 0x0 0x54 0x1 0x0 0x0 0x1 0x1 0x0 0x55 0x1 0x0 0x0 0x1 0x0 0x0 0x56 0x0 0x1 0x0 0x0 0x0 0x0 0x57 0x1 0x1 0x0 0x0 0x0 0x0 0x58 0x1 0x1 0x0 0x0 0x0 0x0 0x59 0x1 0x0 0x0 0x1 0x0 0x0 0x5a 0x1 0x1 0x0 0x1 0x1 0x0 0x5b 0x0 0x0 0x0 0x1 0x1 0x0 0x5c 0x1 0x1 0x0 0x1 0x0 0x0 0x5d 0x1 0x0 0x0 0x1 0x1 0x0 0x5e 0x1 0x0 0x0 0x1 0x1 0x0 0x5f 0x1 0x0 0x0 0x1 0x1 0x0 0x60 0x1 0x1 0x0 0x0 0x0 0x0 0x61 0x0 0x1 0x0 0x0 0x0 0x0 0x62 0x0 0x1 0x0 0x0 0x0 0x0 0x63 0x0 0x1 0x0 0x0 0x0 0x0 0x64 0x0 0x1 0x0 0x0 0x0 0x0 0x65 0x0 0x1 0x0 0x0 0x0 0x0 0x66 0x0 0x1 0x0 0x0 0x0 0x0 0x67 0x1 0x0 0x0 0x0 0x0 0x0 0x68 0x1 0x0 0x0 0x0 0x0 0x0 0x69 0x1 0x0 0x0 0x0 0x0 0x0 0x6a 0x1 0x0 0x0 0x0 0x0 0x0 0x6b 0x0 0x0 0x0 0x1 0x0 0x0 0x6c 0x0 0x1 0x0 0x0 0x0 0x0 0x6d 0x0 0x1 0x0 0x0 0x0 0x0 0x6e 0x0 0x1 0x0 0x0 0x0 0x0 0x6f 0x0 0x0 0x0 0x0 0x0 0x0 0x70 0x7 0x1 0x0 0x0 0x0 0x0 0x71 0x0 0x0 0x0 0x1 0x0 0x0 0x72 0x0 0x0 0x0 0x1 0x0 0x0 0x73 0x0 0x0 0x0 0x1 0x0 0x0 0x74 0x0 0x0 0x0 0x1 0x0 0x0 0x75 0x0 0x0 0x0 0x1 0x0 0x0 0x76 0x0 0x0 0x0 0x1 0x0 0x0 0x77 0x0 0x0 0x0 0x1 0x0 0x0 0x78 0x0 0x0 0x0 0x1 0x0 0x0 0x79 0x0 0x0 0x0 0x1 0x0 0x0 0x7a 0x1 0x0 0x0 0x1 0x1 0x0 0x7b 0x1 0x0 0x0 0x1 0x1 0x0 0x7c 0x1 0x1 0x0 0x0 0x0 0x0 0x7d 0x1 0x0 0x0 0x1 0x1 0x0 0x7e 0x1 0x0 0x0 0x1 0x1 0x0 0x7f 0x1 0x0 0x0 0x1 0x1 0x0 0x80 0x1 0x0 0x0 0x1 0x1 0x0 0x81 0x1 0x0 0x0 0x1 0x1 0x0 0x82 0x1 0x0 0x0 0x1 0x1 0x0 0x83 0x1 0x0 0x0 0x1 0x0 0x0 0x84 0x1 0x0 0x0 0x1 0x1 0x0 0x85 0x1 0x1 0x1 0x0 0x0 0x0 0x86 0x1 0x0 0x0 0x1 0x0 0x1 0x87 0x1 0x1 0x0 0x0 0x0 0x0 0x88 0x1 0x1 0x0 0x1 0x0 0x0 0x89 0x1 0x1 0x0 0x1 0x0 0x0 0x8a 0x1 0x1 0x0 0x0 0x0 0x0 0x8b 0x1 0x1 0x0 0x1 0x0 0x0 0x8c 0x1 0x0 0x0 0x0 0x0 0x0 0x8d 0x1 0x0 0x0 0x0 0x0 0x0 0x8e 0x1 0x0 0x0 0x0 0x0 0x0 0x8f 0x1 0x0 0x0 0x0 0x0 0x0 0x90 0x1 0x0 0x0 0x1 0x0 0x0 0x91 0x1 0x1 0x1 0x0 0x0 0x0 0x92 0x1 0x0 0x0 0x1 0x0 0x0 0x93 0x1 0x1 0x0 0x0 0x0 0x0 0x94 0x1 0x1 0x0 0x0 0x0 0x0 0x95 0x1 0x1 0x0 0x0 0x0 0x0 0x96 0x0 0x1 0x0 0x0 0x0 0x0 0x97 0x0 0x1 0x0 0x0 0x0 0x0 0x98 0x0 0x1 0x0 0x0 0x0 0x0 0x99 0x0 0x1 0x0 0x0 0x0 0x0 0x9a 0x1 0x1 0x0 0x0 0x0 0x0 0x9b 0x0 0x0 0x0 0x1 0x0 0x0 0x9c 0x0 0x1 0x0 0x0 0x0 0x0 0x9d 0x1 0x0 0x0 0x1 0x0 0x0 0x9e 0x0 0x0 0x0 0x1 0x1 0x0 0x9f 0x0 0x1 0x0 0x0 0x0 0x0 0xa0 0x0 0x0 0x0 0x1 0x0 0x0 0xa1 0x2 0x0 0x0 0x1 0x0 0x0 0xa2 0x2 0x1 0x1 0x0 0x0 0x0 0xa3 0x2 0x1 0x0 0x0 0x0 0x0 0xa4 0x2 0x1 0x0 0x0 0x0 0x0 0xa5 0x0 0x1 0x1 0x0 0x0 0x0 0xa6 0x0 0x1 0x0 0x0 0x0 0x0 0xa7 0x1 0x1 0x0 0x1 0x0 0x0 0xa8 0x1 0x1 0x0 0x1 0x0 0x0 0xa9 0x0 0x1 0x0 0x0 0x0 0x0 0xaa 0x2 0x1 0x0 0x1 0x0 0x0 0xab 0x2 0x1 0x0 0x1 0x0 0x0 0xac 0x2 0x1 0x0 0x1 0x0 0x0 0xad 0x0 0x0 0x0 0x1 0x0 0x0 0xae 0x2 0x0 0x0 0x1 0x0 0x0 0xaf 0x0 0x1 0x0 0x0 0x0 0x0 0xb0 0x0 0x1 0x0 0x0 0x0 0x0 0xb1 0x0 0x1 0x0 0x0 0x0 0x0 0xb2 0x0 0x1 0x0 0x0 0x0 0x0 0xb3 0x0 0x1 0x0 0x0 0x0 0x0 0xb4 0x0 0x0 0x0 0x1 0x0 0x0 0xb5 0x0 0x0 0x0 0x1 0x0 0x0 0xb6 0x0 0x0 0x0 0x1 0x0 0x0 0xb7 0x0 0x0 0x0 0x1 0x0 0x0 0xb8 0x0 0x0 0x0 0x1 0x0 0x0 0xb9 0x0 0x0 0x0 0x1 0x0 0x0 0xba 0x0 0x0 0x0 0x1 0x0 0x0 0xbb 0x0 0x0 0x0 0x1 0x0 0x0 0xbc 0x0 0x0 0x0 0x1 0x0 0x0 0xbd 0x0 0x0 0x0 0x1 0x0 0x0 0xbe 0x0 0x0 0x0 0x1 0x0 0x0 0xbf 0x0 0x0 0x0 0x1 0x0 0x0>;
		};
	};

	fragment@61 {
		target = <0xffffffff>;

		__overlay__ {
			deb-gpios = <0xffffffff 0x0 0x0>;
			debounce = <0x7d000>;
			interrupt-parent = <0xffffffff>;
			interrupts = <0x0 0x8 0x0 0x0>;
			status = "okay";
		};
	};

	fragment@62 {
		target = <0xffffffff>;

		__overlay__ {
			interrupt-parent = <0xffffffff>;
			interrupts = <0x1 0x2 0x1 0x0>;
			status = "okay";
		};
	};

	fragment@63 {
		target = <0xffffffff>;

		__overlay__ {
			deb-gpios = <0xffffffff 0x3 0x0>;
			debounce = <0x3e800>;
			interrupt-parent = <0xffffffff>;
			interrupts = <0x3 0x8 0x3 0x0>;
			status = "okay";
		};
	};

	fragment@64 {
		target = <0xffffffff>;

		__overlay__ {
			interrupt-parent = <0xffffffff>;
			interrupts = <0x4 0x8 0x4 0x0>;
			status = "okay";
		};
	};

	fragment@65 {
		target = <0xffffffff>;

		__overlay__ {
			deb-gpios = <0xffffffff 0x7 0x0>;
			debounce = <0x3e800>;
			interrupt-parent = <0xffffffff>;
			interrupts = <0x7 0x8 0x7 0x0>;
			status = "okay";
		};
	};

	fragment@66 {
		target = <0xffffffff>;

		__overlay__ {
			interrupt-parent = <0xffffffff>;
			interrupts = <0x9 0x8 0x9 0x0>;
			status = "okay";
		};
	};

	fragment@67 {
		target = <0xffffffff>;

		__overlay__ {
			interrupt-parent = <0xffffffff>;
			interrupts = <0x14 0x1 0x14 0x0>;
			status = "okay";
		};
	};

	fragment@68 {
		target = <0xffffffff>;

		__overlay__ {
			interrupt-parent = <0xffffffff>;
			interrupts = <0x29 0x2 0x29 0x0>;
			status = "okay";
		};
	};

	fragment@69 {
		target = <0xffffffff>;

		__overlay__ {
			deb-gpios = <0xffffffff 0x37 0x0>;
			debounce = <0x7d000>;
			interrupt-parent = <0xffffffff>;
			interrupts = <0x37 0x4 0x37 0x0>;
			status = "okay";
		};
	};

	fragment@7 {
		target = <0xffffffff>;

		__overlay__ {
			#address-cells = <0x1>;
			#size-cells = <0x0>;

			tfa98xx@35 {
				compatible = "nxp,tfa98xx";
				pinctrl-0 = <0x1a>;
				pinctrl-1 = <0x1b>;
				pinctrl-2 = <0x1c>;
				pinctrl-names = "tfa98xx_reset_default", "tfa98xx_reset_high", "tfa98xx_reset_low";
				reg = <0x35>;
				status = "okay";
			};
		};
	};

	fragment@70 {
		target = <0xffffffff>;

		__overlay__ {
			interrupt-parent = <0xffffffff>;
			interrupts = <0xb6 0x4 0xbe 0x0>;
			status = "okay";
		};
	};

	fragment@71 {
		target = <0xffffffff>;

		__overlay__ {
			interrupt-parent = <0xffffffff>;
			interrupts = <0xba 0x8 0xad 0x0>;
			status = "okay";
		};
	};

	fragment@72 {
		target = <0xffffffff>;

		__overlay__ {
			compatible = "mediatek,md1_sim1_hot_plug_eint-eint";
			debounce = <0x0 0x186a0>;
			dedicated = <0x0 0x0>;
			interrupts = <0x0 0x8>;
			sockettype = <0x0 0x0>;
			src_pin = <0x0 0x1>;
			status = "okay";
		};
	};

	fragment@73 {
		target = <0xffffffff>;

		__overlay__ {
			compatible = "mediatek,md1_sim2_hot_plug_eint-eint";
			debounce = <0x1 0x186a0>;
			dedicated = <0x1 0x0>;
			interrupts = <0x1 0x8>;
			sockettype = <0x1 0x0>;
			src_pin = <0x1 0x2>;
			status = "okay";
		};
	};

	fragment@74 {
		target = <0xffffffff>;

		__overlay__ {
			regulator-default-on = <0x1>;
			regulator-name = "vcama1";
			status = "okay";
		};
	};

	fragment@75 {
		target = <0xffffffff>;

		__overlay__ {
			regulator-default-on = <0x1>;
			regulator-name = "vcama2";
			status = "okay";
		};
	};

	fragment@76 {
		target = <0xffffffff>;

		__overlay__ {
			regulator-default-on = <0x1>;
			regulator-name = "vsim1";
			status = "okay";
		};
	};

	fragment@77 {
		target = <0xffffffff>;

		__overlay__ {
			regulator-default-on = <0x1>;
			regulator-name = "vsim2";
			status = "okay";
		};
	};

	fragment@78 {
		target = <0xffffffff>;

		__overlay__ {
			regulator-default-on = <0x1>;
			regulator-name = "vcamd";
			status = "okay";
		};
	};

	fragment@79 {
		target = <0xffffffff>;

		__overlay__ {
			regulator-default-on = <0x1>;
			regulator-name = "vcamio";
			status = "okay";
		};
	};

	fragment@8 {
		target = <0xffffffff>;

		__overlay__ {

			tfa98xxrstdefault {
				phandle = <0x1a>;
			};

			tfa98xxrsthigh {
				phandle = <0x1b>;

				pins_cmd_dat {
					output-high;
					pinmux = <0x9c00>;
					slew-rate = <0x1>;
				};
			};

			tfa98xxrstlow {
				phandle = <0x1c>;

				pins_cmd_dat {
					output-low;
					pinmux = <0x9c00>;
					slew-rate = <0x1>;
				};
			};
		};
	};

	fragment@80 {
		target = <0xffffffff>;

		__overlay__ {
			regulator-default-on = <0x1>;
			regulator-name = "vldo28";
			status = "okay";
		};
	};

	fragment@81 {
		target = <0xffffffff>;

		__overlay__ {
			status = "okay";
			vcama-supply = <0xffffffff>;
			vcama_main2-supply = <0xffffffff>;
			vcama_sub-supply = <0xffffffff>;
			vcamaf-supply = <0xffffffff>;
			vcamd_main2-supply = <0xffffffff>;
			vcamio-supply = <0xffffffff>;
			vcamio_main2-supply = <0xffffffff>;
			vcamio_sub-supply = <0xffffffff>;
		};
	};

	fragment@82 {
		target = <0xffffffff>;

		__overlay__ {
			status = "okay";
			vtouch-supply = <0xffffffff>;
		};
	};

	fragment@83 {
		target = <0xffffffff>;

		__overlay__ {
			mediatek,kpd-hw-dl-key0 = <0x11>;
			mediatek,kpd-hw-dl-key1 = <0x0>;
			mediatek,kpd-hw-dl-key2 = <0x8>;
			mediatek,kpd-hw-factory-key = <0x0>;
			mediatek,kpd-hw-init-map = <0x72 0x0 0x0 0x0 0x0 0x0 0x0 0x0 0x0 0x0 0x0 0x0 0x0 0x0 0x0 0x0 0x0 0x0 0x0 0x0 0x0 0x0 0x0 0x0 0x0 0x0 0x0 0x0 0x0 0x0 0x0 0x0 0x0 0x0 0x0 0x0 0x0 0x0 0x0 0x0 0x0 0x0 0x0 0x0 0x0 0x0 0x0 0x0 0x0 0x0 0x0 0x0 0x0 0x0 0x0 0x0 0x0 0x0 0x0 0x0 0x0 0x0 0x0 0x0 0x0 0x0 0x0 0x0 0x0 0x0 0x0 0x0>;
			mediatek,kpd-hw-map-num = <0x48>;
			mediatek,kpd-hw-pwrkey = <0x8>;
			mediatek,kpd-hw-recovery-key = <0x11>;
			mediatek,kpd-hw-rstkey = <0x11>;
			mediatek,kpd-key-debounce = <0x400>;
			mediatek,kpd-pwkey-gpio-din = <0x0>;
			mediatek,kpd-pwrkey-eint-gpio = <0x0>;
			mediatek,kpd-sw-pwrkey = <0x74>;
			mediatek,kpd-sw-rstkey = <0x73>;
			mediatek,kpd-use-extend-type = <0x0>;
			status = "okay";
		};
	};

	fragment@84 {
		target = <0xffffffff>;

		__overlay__ {
			pinctrl-0 = <0x6e>;
			pinctrl-1 = <0x6f>;
			pinctrl-names = "i2c-state", "output-low-state";
		};
	};

	fragment@85 {
		target = <0xffffffff>;

		__overlay__ {

			i2c6_sda_i2c_state {
				phandle = <0x6e>;

				pins_cmd_dat {
					bias-disable;
					pinmux = <0xc03>;
					slew-rate = <0x0>;
				};
			};

			i2c6_sda_output_low_state {
				phandle = <0x6f>;

				pins_cmd_dat {
					output-low;
					pinmux = <0xc00>;
					slew-rate = <0x1>;
				};
			};
		};
	};

	fragment@86 {
		target = <0xffffffff>;

		__overlay__ {

			active@id1 {
				phandle = <0x4>;

				pins_cmd_dat {
					bias-pull-up;
					input-enable;
					pinmux = <0x4100>;
					slew-rate = <0x0>;
				};
			};

			active@id2 {
				phandle = <0x5>;

				pins_cmd_dat {
					bias-pull-up;
					input-enable;
					pinmux = <0x3a00>;
					slew-rate = <0x0>;
				};
			};

			default@hw_sub_id {
				phandle = <0x1>;
			};

			sleep@id1 {
				phandle = <0x2>;

				pins_cmd_dat {
					bias-pull-down;
					input-enable;
					pinmux = <0x4100>;
					slew-rate = <0x0>;
				};
			};

			sleep@id2 {
				phandle = <0x3>;

				pins_cmd_dat {
					bias-pull-down;
					input-enable;
					pinmux = <0x3a00>;
				};
			};
		};
	};

	fragment@87 {
		target = <0xffffffff>;

		__overlay__ {
			compatible = "mediatek, swtp-eint";
		};
	};

	fragment@9 {
		target = <0xffffffff>;

		__overlay__ {

			bq25601d-charger@6b {
				chg-irq-gpio = <0xffffffff 0x5b 0x2002>;
				chip-name = "BQ25601D";
				compatible = "oppo,bq25601d-charger";
				interrupt-parent = <0xffffffff>;
				interrupts = <0x5b 0x2 0x5b 0x0>;
				reg = <0x6b>;
				status = "okay";
			};

			bq25890h-charger@6a {
				chg-irq-gpio = <0xffffffff 0x5b 0x2002>;
				chip-name = "BQ25890H";
				compatible = "oppo,bq25890h-charger";
				interrupt-parent = <0xffffffff>;
				interrupts = <0x5b 0x2 0x5b 0x0>;
				reg = <0x6a>;
				status = "okay";
			};
		};
	};
};
